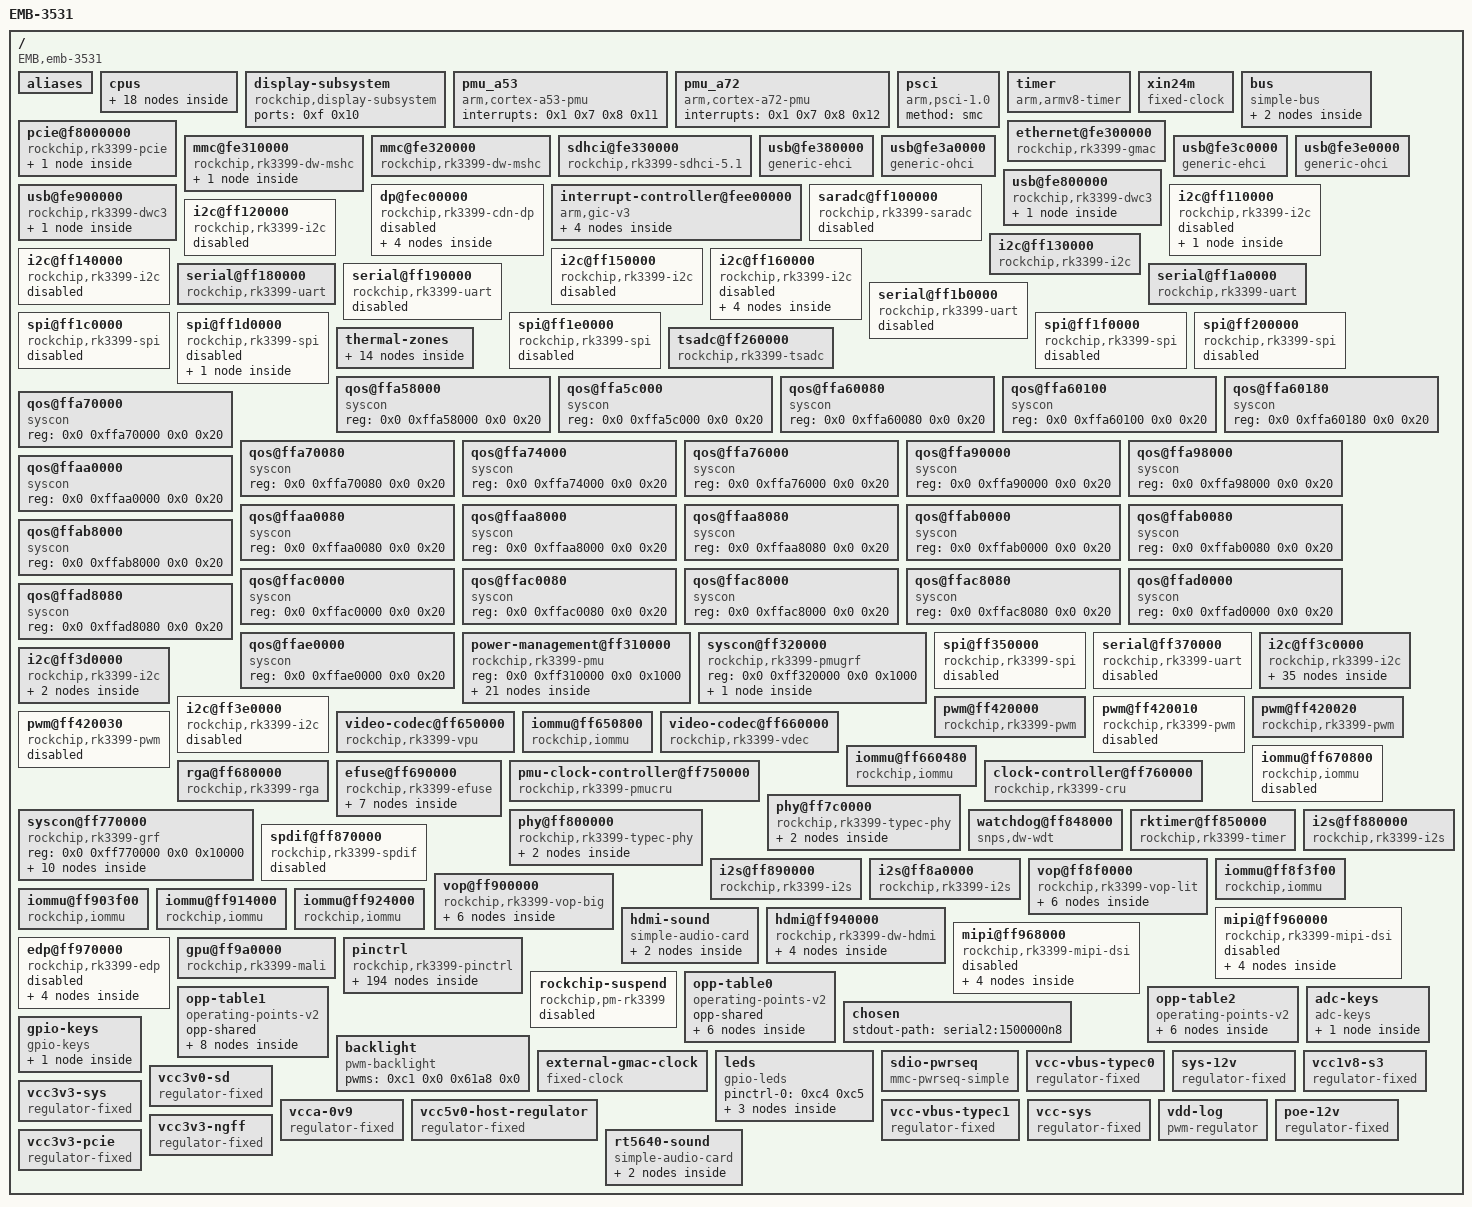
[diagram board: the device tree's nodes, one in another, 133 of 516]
/dts-v1/;

/ {
	compatible = "EMB,emb-3531", "rockchip,rk3399";
	interrupt-parent = <0x1>;
	#address-cells = <0x2>;
	#size-cells = <0x2>;
	model = "EMB-3531";

	aliases {
		ethernet0 = "/ethernet@fe300000";
		i2c0 = "/i2c@ff3c0000";
		i2c1 = "/i2c@ff110000";
		i2c2 = "/i2c@ff120000";
		i2c3 = "/i2c@ff130000";
		i2c4 = "/i2c@ff3d0000";
		i2c5 = "/i2c@ff140000";
		i2c6 = "/i2c@ff150000";
		i2c7 = "/i2c@ff160000";
		i2c8 = "/i2c@ff3e0000";
		mmc0 = "/mmc@fe310000";
		mmc1 = "/mmc@fe320000";
		mmc2 = "/sdhci@fe330000";
		serial0 = "/serial@ff180000";
		serial1 = "/serial@ff190000";
		serial2 = "/serial@ff1a0000";
		serial3 = "/serial@ff1b0000";
		serial4 = "/serial@ff370000";
	};

	cpus {
		#address-cells = <0x2>;
		#size-cells = <0x0>;

		cpu-map {

			cluster0 {

				core0 {
					cpu = <0x2>;
				};

				core1 {
					cpu = <0x3>;
				};

				core2 {
					cpu = <0x4>;
				};

				core3 {
					cpu = <0x5>;
				};
			};

			cluster1 {

				core0 {
					cpu = <0x6>;
				};

				core1 {
					cpu = <0x7>;
				};
			};
		};

		cpu@0 {
			device_type = "cpu";
			compatible = "arm,cortex-a53";
			reg = <0x0 0x0>;
			enable-method = "psci";
			capacity-dmips-mhz = <0x1e5>;
			clocks = <0x8 0x8>;
			#cooling-cells = <0x2>;
			dynamic-power-coefficient = <0x64>;
			cpu-idle-states = <0x9 0xa>;
			operating-points-v2 = <0xb>;
			cpu-supply = <0xc>;
			phandle = <0x2>;
		};

		cpu@1 {
			device_type = "cpu";
			compatible = "arm,cortex-a53";
			reg = <0x0 0x1>;
			enable-method = "psci";
			capacity-dmips-mhz = <0x1e5>;
			clocks = <0x8 0x8>;
			#cooling-cells = <0x2>;
			dynamic-power-coefficient = <0x64>;
			cpu-idle-states = <0x9 0xa>;
			operating-points-v2 = <0xb>;
			cpu-supply = <0xc>;
			phandle = <0x3>;
		};

		cpu@2 {
			device_type = "cpu";
			compatible = "arm,cortex-a53";
			reg = <0x0 0x2>;
			enable-method = "psci";
			capacity-dmips-mhz = <0x1e5>;
			clocks = <0x8 0x8>;
			#cooling-cells = <0x2>;
			dynamic-power-coefficient = <0x64>;
			cpu-idle-states = <0x9 0xa>;
			operating-points-v2 = <0xb>;
			cpu-supply = <0xc>;
			phandle = <0x4>;
		};

		cpu@3 {
			device_type = "cpu";
			compatible = "arm,cortex-a53";
			reg = <0x0 0x3>;
			enable-method = "psci";
			capacity-dmips-mhz = <0x1e5>;
			clocks = <0x8 0x8>;
			#cooling-cells = <0x2>;
			dynamic-power-coefficient = <0x64>;
			cpu-idle-states = <0x9 0xa>;
			operating-points-v2 = <0xb>;
			cpu-supply = <0xc>;
			phandle = <0x5>;
		};

		cpu@100 {
			device_type = "cpu";
			compatible = "arm,cortex-a72";
			reg = <0x0 0x100>;
			enable-method = "psci";
			capacity-dmips-mhz = <0x400>;
			clocks = <0x8 0x9>;
			#cooling-cells = <0x2>;
			dynamic-power-coefficient = <0x1b4>;
			cpu-idle-states = <0x9 0xa>;
			operating-points-v2 = <0xd>;
			cpu-supply = <0xe>;
			phandle = <0x6>;
		};

		cpu@101 {
			device_type = "cpu";
			compatible = "arm,cortex-a72";
			reg = <0x0 0x101>;
			enable-method = "psci";
			capacity-dmips-mhz = <0x400>;
			clocks = <0x8 0x9>;
			#cooling-cells = <0x2>;
			dynamic-power-coefficient = <0x1b4>;
			cpu-idle-states = <0x9 0xa>;
			operating-points-v2 = <0xd>;
			cpu-supply = <0xe>;
			phandle = <0x7>;
		};

		idle-states {
			entry-method = "psci";

			cpu-sleep {
				compatible = "arm,idle-state";
				local-timer-stop;
				arm,psci-suspend-param = <0x10000>;
				entry-latency-us = <0x78>;
				exit-latency-us = <0xfa>;
				min-residency-us = <0x384>;
				phandle = <0x9>;
			};

			cluster-sleep {
				compatible = "arm,idle-state";
				local-timer-stop;
				arm,psci-suspend-param = <0x1010000>;
				entry-latency-us = <0x190>;
				exit-latency-us = <0x1f4>;
				min-residency-us = <0x7d0>;
				phandle = <0xa>;
			};
		};
	};

	display-subsystem {
		compatible = "rockchip,display-subsystem";
		ports = <0xf 0x10>;
	};

	pmu_a53 {
		compatible = "arm,cortex-a53-pmu";
		interrupts = <0x1 0x7 0x8 0x11>;
	};

	pmu_a72 {
		compatible = "arm,cortex-a72-pmu";
		interrupts = <0x1 0x7 0x8 0x12>;
	};

	psci {
		compatible = "arm,psci-1.0";
		method = "smc";
	};

	timer {
		compatible = "arm,armv8-timer";
		interrupts = <0x1 0xd 0x8 0x0 0x1 0xe 0x8 0x0 0x1 0xb 0x8 0x0 0x1 0xa 0x8 0x0>;
		arm,no-tick-in-suspend;
	};

	xin24m {
		compatible = "fixed-clock";
		clock-frequency = <0x16e3600>;
		clock-output-names = "xin24m";
		#clock-cells = <0x0>;
		phandle = <0xd4>;
	};

	bus {
		compatible = "simple-bus";
		#address-cells = <0x2>;
		#size-cells = <0x2>;
		ranges;
		phandle = <0xd5>;

		dma-controller@ff6d0000 {
			compatible = "arm,pl330", "arm,primecell";
			reg = <0x0 0xff6d0000 0x0 0x4000>;
			interrupts = <0x0 0x5 0x4 0x0 0x0 0x6 0x4 0x0>;
			#dma-cells = <0x1>;
			arm,pl330-periph-burst;
			clocks = <0x8 0xd3>;
			clock-names = "apb_pclk";
			phandle = <0x62>;
		};

		dma-controller@ff6e0000 {
			compatible = "arm,pl330", "arm,primecell";
			reg = <0x0 0xff6e0000 0x0 0x4000>;
			interrupts = <0x0 0x7 0x4 0x0 0x0 0x8 0x4 0x0>;
			#dma-cells = <0x1>;
			arm,pl330-periph-burst;
			clocks = <0x8 0xd4>;
			clock-names = "apb_pclk";
			phandle = <0x51>;
		};
	};

	pcie@f8000000 {
		compatible = "rockchip,rk3399-pcie";
		reg = <0x0 0xf8000000 0x0 0x2000000 0x0 0xfd000000 0x0 0x1000000>;
		reg-names = "axi-base", "apb-base";
		device_type = "pci";
		#address-cells = <0x3>;
		#size-cells = <0x2>;
		#interrupt-cells = <0x1>;
		aspm-no-l0s;
		bus-range = <0x0 0x1f>;
		clocks = <0x8 0xc5 0x8 0xc4 0x8 0x147 0x8 0xa0>;
		clock-names = "aclk", "aclk-perf", "hclk", "pm";
		interrupts = <0x0 0x31 0x4 0x0 0x0 0x32 0x4 0x0 0x0 0x33 0x4 0x0>;
		interrupt-names = "sys", "legacy", "client";
		interrupt-map-mask = <0x0 0x0 0x0 0x7>;
		interrupt-map = <0x0 0x0 0x0 0x1 0x13 0x0 0x0 0x0 0x0 0x2 0x13 0x1 0x0 0x0 0x0 0x3 0x13 0x2 0x0 0x0 0x0 0x4 0x13 0x3>;
		max-link-speed = <0x2>;
		msi-map = <0x0 0x14 0x0 0x1000>;
		phys = <0x15 0x0 0x15 0x1 0x15 0x2 0x15 0x3>;
		phy-names = "pcie-phy-0", "pcie-phy-1", "pcie-phy-2", "pcie-phy-3";
		ranges = <0x83000000 0x0 0xfa000000 0x0 0xfa000000 0x0 0x1e00000 0x81000000 0x0 0xfbe00000 0x0 0xfbe00000 0x0 0x100000>;
		resets = <0x8 0x82 0x8 0x83 0x8 0x84 0x8 0x85 0x8 0x86 0x8 0x81 0x8 0x80>;
		reset-names = "core", "mgmt", "mgmt-sticky", "pipe", "pm", "pclk", "aclk";
		status = "okay";
		ep-gpios = <0x16 0x19 0x0>;
		num-lanes = <0x4>;
		pinctrl-names = "default";
		pinctrl-0 = <0x17>;
		vpcie3v3-supply = <0x18>;
		vpcie1v8-supply = <0x19>;
		vpcie0v9-supply = <0x1a>;
		phandle = <0xd6>;

		interrupt-controller {
			interrupt-controller;
			#address-cells = <0x0>;
			#interrupt-cells = <0x1>;
			phandle = <0x13>;
		};
	};

	ethernet@fe300000 {
		compatible = "rockchip,rk3399-gmac";
		reg = <0x0 0xfe300000 0x0 0x10000>;
		interrupts = <0x0 0xc 0x4 0x0>;
		interrupt-names = "macirq";
		clocks = <0x8 0x69 0x8 0x67 0x8 0x68 0x8 0x66 0x8 0x6a 0x8 0xd5 0x8 0x166>;
		clock-names = "stmmaceth", "mac_clk_rx", "mac_clk_tx", "clk_mac_ref", "clk_mac_refout", "aclk_mac", "pclk_mac";
		power-domains = <0x1b 0x16>;
		resets = <0x8 0x89>;
		reset-names = "stmmaceth";
		rockchip,grf = <0x1c>;
		snps,txpbl = <0x4>;
		status = "okay";
		assigned-clocks = <0x8 0xa6>;
		assigned-clock-parents = <0x1d>;
		clock_in_out = "input";
		phy-supply = <0x1e>;
		phy-mode = "rgmii";
		pinctrl-names = "default";
		pinctrl-0 = <0x1f>;
		snps,reset-gpio = <0x20 0xf 0x1>;
		snps,reset-active-low;
		snps,reset-delays-us = <0x0 0x2710 0xc350>;
		tx_delay = <0x28>;
		rx_delay = <0x11>;
		phandle = <0xd7>;
	};

	mmc@fe310000 {
		compatible = "rockchip,rk3399-dw-mshc", "rockchip,rk3288-dw-mshc";
		reg = <0x0 0xfe310000 0x0 0x4000>;
		interrupts = <0x0 0x40 0x4 0x0>;
		max-frequency = <0x8f0d180>;
		clocks = <0x8 0x1ee 0x8 0x4d 0x8 0x9c 0x8 0x9d>;
		clock-names = "biu", "ciu", "ciu-drive", "ciu-sample";
		fifo-depth = <0x100>;
		power-domains = <0x1b 0x1c>;
		resets = <0x8 0x79>;
		reset-names = "reset";
		status = "okay";
		bus-width = <0x4>;
		cap-sd-highspeed;
		cap-sdio-irq;
		keep-power-in-suspend;
		mmc-pwrseq = <0x21>;
		non-removable;
		pinctrl-names = "default";
		pinctrl-0 = <0x22 0x23 0x24>;
		sd-uhs-sdr104;
		vmmc-supply = "/i2c@ff3c0000/pmic@1b/regulators/LDO_REG4";
		vqmmc-supply = "/vcc1v8-s3";
		num-slots = <0x1>;
		phandle = <0xd8>;

		wifi@1 {
			compatible = "brcm,bcm4329-fmac";
			interrupt-parent = <0x25>;
			interrupts = <0x3 0x0>;
			interrupt-names = "host-wake";
			brcm,drive-strength = <0x5>;
			pinctrl-names = "default";
			pinctrl-0 = <0x26>;
			phandle = <0xd9>;
		};
	};

	mmc@fe320000 {
		compatible = "rockchip,rk3399-dw-mshc", "rockchip,rk3288-dw-mshc";
		reg = <0x0 0xfe320000 0x0 0x4000>;
		interrupts = <0x0 0x41 0x4 0x0>;
		max-frequency = <0x8f0d180>;
		assigned-clocks = <0x8 0x1cd>;
		assigned-clock-rates = <0xbebc200>;
		clocks = <0x8 0x1ce 0x8 0x4c 0x8 0x9a 0x8 0x9b>;
		clock-names = "biu", "ciu", "ciu-drive", "ciu-sample";
		fifo-depth = <0x100>;
		power-domains = <0x1b 0x1b>;
		resets = <0x8 0x7a>;
		reset-names = "reset";
		status = "okay";
		bus-width = <0x4>;
		cap-sd-highspeed;
		cd-gpios = <0x25 0x7 0x1>;
		disable-wp;
		pinctrl-names = "default";
		pinctrl-0 = <0x27 0x28 0x29>;
		sd-uhs-sdr104;
		vmmc-supply = <0x2a>;
		vqmmc-supply = <0x2b>;
		phandle = <0xda>;
	};

	sdhci@fe330000 {
		compatible = "rockchip,rk3399-sdhci-5.1", "arasan,sdhci-5.1";
		reg = <0x0 0xfe330000 0x0 0x10000>;
		interrupts = <0x0 0xb 0x4 0x0>;
		arasan,soc-ctl-syscon = <0x1c>;
		assigned-clocks = <0x8 0x4e>;
		assigned-clock-rates = <0xbebc200>;
		clocks = <0x8 0x4e 0x8 0xf0>;
		clock-names = "clk_xin", "clk_ahb";
		clock-output-names = "emmc_cardclock";
		#clock-cells = <0x0>;
		phys = <0x2c>;
		phy-names = "phy_arasan";
		power-domains = <0x1b 0x17>;
		disable-cqe-dcmd;
		status = "okay";
		bus-width = <0x8>;
		non-removable;
		phandle = <0x9b>;
	};

	usb@fe380000 {
		compatible = "generic-ehci";
		reg = <0x0 0xfe380000 0x0 0x20000>;
		interrupts = <0x0 0x1a 0x4 0x0>;
		clocks = <0x8 0x1c8 0x8 0x1c9 0x2d>;
		phys = <0x2e>;
		phy-names = "usb";
		status = "okay";
		phandle = <0xdb>;
	};

	usb@fe3a0000 {
		compatible = "generic-ohci";
		reg = <0x0 0xfe3a0000 0x0 0x20000>;
		interrupts = <0x0 0x1c 0x4 0x0>;
		clocks = <0x8 0x1c8 0x8 0x1c9 0x2d>;
		phys = <0x2e>;
		phy-names = "usb";
		status = "okay";
		phandle = <0xdc>;
	};

	usb@fe3c0000 {
		compatible = "generic-ehci";
		reg = <0x0 0xfe3c0000 0x0 0x20000>;
		interrupts = <0x0 0x1e 0x4 0x0>;
		clocks = <0x8 0x1ca 0x8 0x1cb 0x2f>;
		phys = <0x30>;
		phy-names = "usb";
		status = "okay";
		phandle = <0xdd>;
	};

	usb@fe3e0000 {
		compatible = "generic-ohci";
		reg = <0x0 0xfe3e0000 0x0 0x20000>;
		interrupts = <0x0 0x20 0x4 0x0>;
		clocks = <0x8 0x1ca 0x8 0x1cb 0x2f>;
		phys = <0x30>;
		phy-names = "usb";
		status = "okay";
		phandle = <0xde>;
	};

	usb@fe800000 {
		compatible = "rockchip,rk3399-dwc3";
		#address-cells = <0x2>;
		#size-cells = <0x2>;
		ranges;
		clocks = <0x8 0x81 0x8 0x83 0x8 0xf6 0x8 0xf8 0x8 0xf4 0x8 0xf9>;
		clock-names = "ref_clk", "suspend_clk", "bus_clk", "aclk_usb3_rksoc_axi_perf", "aclk_usb3", "grf_clk";
		resets = <0x8 0x125>;
		reset-names = "usb3-otg";
		status = "okay";
		phandle = <0xdf>;

		usb@fe800000 {
			compatible = "snps,dwc3";
			reg = <0x0 0xfe800000 0x0 0x100000>;
			interrupts = <0x0 0x69 0x4 0x0>;
			clocks = <0x8 0x81 0x8 0xf6 0x8 0x83>;
			clock-names = "ref", "bus_early", "suspend";
			dr_mode = "otg";
			phys = <0x31 0x32>;
			phy-names = "usb2-phy", "usb3-phy";
			phy_type = "utmi_wide";
			snps,dis_enblslpm_quirk;
			snps,dis-u2-freeclk-exists-quirk;
			snps,dis_u2_susphy_quirk;
			snps,dis-del-phy-power-chg-quirk;
			snps,dis-tx-ipgap-linecheck-quirk;
			snps,xhci-trb-ent-quirk;
			power-domains = <0x1b 0x18>;
			status = "okay";
			phandle = <0xe0>;
		};
	};

	usb@fe900000 {
		compatible = "rockchip,rk3399-dwc3";
		#address-cells = <0x2>;
		#size-cells = <0x2>;
		ranges;
		clocks = <0x8 0x82 0x8 0x84 0x8 0xf7 0x8 0xf8 0x8 0xf4 0x8 0xf9>;
		clock-names = "ref_clk", "suspend_clk", "bus_clk", "aclk_usb3_rksoc_axi_perf", "aclk_usb3", "grf_clk";
		resets = <0x8 0x126>;
		reset-names = "usb3-otg";
		status = "okay";
		phandle = <0xe1>;

		usb@fe900000 {
			compatible = "snps,dwc3";
			reg = <0x0 0xfe900000 0x0 0x100000>;
			interrupts = <0x0 0x6e 0x4 0x0>;
			clocks = <0x8 0x82 0x8 0xf7 0x8 0x84>;
			clock-names = "ref", "bus_early", "suspend";
			dr_mode = "host";
			phys = <0x33 0x34>;
			phy-names = "usb2-phy", "usb3-phy";
			phy_type = "utmi_wide";
			snps,dis_enblslpm_quirk;
			snps,dis-u2-freeclk-exists-quirk;
			snps,dis_u2_susphy_quirk;
			snps,dis-del-phy-power-chg-quirk;
			snps,dis-tx-ipgap-linecheck-quirk;
			snps,xhci-trb-ent-quirk;
			power-domains = <0x1b 0x18>;
			status = "okay";
			phandle = <0xe2>;
		};
	};

	dp@fec00000 {
		compatible = "rockchip,rk3399-cdn-dp";
		reg = <0x0 0xfec00000 0x0 0x100000>;
		interrupts = <0x0 0x9 0x4 0x0>;
		assigned-clocks = <0x8 0x72 0x8 0xa1>;
		assigned-clock-rates = <0x5f5e100 0xbebc200>;
		clocks = <0x8 0x72 0x8 0x175 0x8 0xa1 0x8 0x16f>;
		clock-names = "core-clk", "pclk", "spdif", "grf";
		phys = <0x35 0x36>;
		power-domains = <0x1b 0x15>;
		resets = <0x8 0x103 0x8 0x148 0x8 0x14a 0x8 0xfd>;
		reset-names = "spdif", "dptx", "apb", "core";
		rockchip,grf = <0x1c>;
		#sound-dai-cells = <0x1>;
		status = "disabled";
		phandle = <0xe3>;

		ports {

			port {
				#address-cells = <0x1>;
				#size-cells = <0x0>;
				phandle = <0xe4>;

				endpoint@0 {
					reg = <0x0>;
					remote-endpoint = <0x37>;
					phandle = <0xaa>;
				};

				endpoint@1 {
					reg = <0x1>;
					remote-endpoint = <0x38>;
					phandle = <0xa4>;
				};
			};
		};
	};

	interrupt-controller@fee00000 {
		compatible = "arm,gic-v3";
		#interrupt-cells = <0x4>;
		#address-cells = <0x2>;
		#size-cells = <0x2>;
		ranges;
		interrupt-controller;
		reg = <0x0 0xfee00000 0x0 0x10000 0x0 0xfef00000 0x0 0xc0000 0x0 0xfff00000 0x0 0x10000 0x0 0xfff10000 0x0 0x10000 0x0 0xfff20000 0x0 0x10000>;
		interrupts = <0x1 0x9 0x4 0x0>;
		phandle = <0x1>;

		interrupt-controller@fee20000 {
			compatible = "arm,gic-v3-its";
			msi-controller;
			#msi-cells = <0x1>;
			reg = <0x0 0xfee20000 0x0 0x20000>;
			phandle = <0x14>;
		};

		ppi-partitions {

			interrupt-partition-0 {
				affinity = <0x2 0x3 0x4 0x5>;
				phandle = <0x11>;
			};

			interrupt-partition-1 {
				affinity = <0x6 0x7>;
				phandle = <0x12>;
			};
		};
	};

	saradc@ff100000 {
		compatible = "rockchip,rk3399-saradc";
		reg = <0x0 0xff100000 0x0 0x100>;
		interrupts = <0x0 0x3e 0x4 0x0>;
		#io-channel-cells = <0x1>;
		clocks = <0x8 0x50 0x8 0x165>;
		clock-names = "saradc", "apb_pclk";
		resets = <0x8 0xd4>;
		reset-names = "saradc-apb";
		status = "disabled";
		vref-supply = <0x39>;
		phandle = <0xc2>;
	};

	i2c@ff110000 {
		compatible = "rockchip,rk3399-i2c";
		reg = <0x0 0xff110000 0x0 0x1000>;
		assigned-clocks = <0x8 0x41>;
		assigned-clock-rates = <0xbebc200>;
		clocks = <0x8 0x41 0x8 0x155>;
		clock-names = "i2c", "pclk";
		interrupts = <0x0 0x3b 0x4 0x0>;
		pinctrl-names = "default";
		pinctrl-0 = <0x3a>;
		#address-cells = <0x1>;
		#size-cells = <0x0>;
		status = "disabled";
		i2c-scl-rising-time-ns = <0x12c>;
		i2c-scl-falling-time-ns = <0xf>;
		phandle = <0xe5>;

		rt5640@1c {
			compatible = "realtek,rt5640";
			reg = <0x1c>;
			clocks = <0x8 0x59>;
			clock-names = "mclk";
			realtek,in1-differential;
			#sound-dai-cells = <0x0>;
			pinctrl-names = "default";
			pinctrl-0 = <0x3b>;
			phandle = <0xd3>;
		};
	};

	i2c@ff120000 {
		compatible = "rockchip,rk3399-i2c";
		reg = <0x0 0xff120000 0x0 0x1000>;
		assigned-clocks = <0x8 0x42>;
		assigned-clock-rates = <0xbebc200>;
		clocks = <0x8 0x42 0x8 0x156>;
		clock-names = "i2c", "pclk";
		interrupts = <0x0 0x23 0x4 0x0>;
		pinctrl-names = "default";
		pinctrl-0 = <0x3c>;
		#address-cells = <0x1>;
		#size-cells = <0x0>;
		status = "disabled";
		phandle = <0xe6>;
	};

	i2c@ff130000 {
		compatible = "rockchip,rk3399-i2c";
		reg = <0x0 0xff130000 0x0 0x1000>;
		assigned-clocks = <0x8 0x43>;
		assigned-clock-rates = <0xbebc200>;
		clocks = <0x8 0x43 0x8 0x157>;
		clock-names = "i2c", "pclk";
		interrupts = <0x0 0x22 0x4 0x0>;
		pinctrl-names = "default";
		pinctrl-0 = <0x3d>;
		#address-cells = <0x1>;
		#size-cells = <0x0>;
		status = "okay";
		i2c-scl-rising-time-ns = <0x1c2>;
		i2c-scl-falling-time-ns = <0xf>;
		phandle = <0xad>;
	};

	i2c@ff140000 {
		compatible = "rockchip,rk3399-i2c";
		reg = <0x0 0xff140000 0x0 0x1000>;
		assigned-clocks = <0x8 0x44>;
		assigned-clock-rates = <0xbebc200>;
		clocks = <0x8 0x44 0x8 0x158>;
		clock-names = "i2c", "pclk";
		interrupts = <0x0 0x26 0x4 0x0>;
		pinctrl-names = "default";
		pinctrl-0 = <0x3e>;
		#address-cells = <0x1>;
		#size-cells = <0x0>;
		status = "disabled";
		phandle = <0xe7>;
	};

	i2c@ff150000 {
		compatible = "rockchip,rk3399-i2c";
		reg = <0x0 0xff150000 0x0 0x1000>;
		assigned-clocks = <0x8 0x45>;
		assigned-clock-rates = <0xbebc200>;
		clocks = <0x8 0x45 0x8 0x159>;
		clock-names = "i2c", "pclk";
		interrupts = <0x0 0x25 0x4 0x0>;
		pinctrl-names = "default";
		pinctrl-0 = <0x3f>;
		#address-cells = <0x1>;
		#size-cells = <0x0>;
		status = "disabled";
		phandle = <0xe8>;
	};

	i2c@ff160000 {
		compatible = "rockchip,rk3399-i2c";
		reg = <0x0 0xff160000 0x0 0x1000>;
		assigned-clocks = <0x8 0x46>;
		assigned-clock-rates = <0xbebc200>;
		clocks = <0x8 0x46 0x8 0x15a>;
		clock-names = "i2c", "pclk";
		interrupts = <0x0 0x24 0x4 0x0>;
		pinctrl-names = "default";
		pinctrl-0 = <0x40>;
		#address-cells = <0x1>;
		#size-cells = <0x0>;
		status = "disabled";
		i2c-scl-rising-time-ns = <0x258>;
		i2c-scl-falling-time-ns = <0x14>;
		phandle = <0xe9>;

		usb-typec@22 {
			compatible = "fairchild,fusb302";
			reg = <0x22>;
			interrupt-parent = <0x41>;
			interrupts = <0x2 0x8>;
			pinctrl-names = "default";
			pinctrl-0 = <0x42>;
			vbus-supply = <0x43>;
			status = "okay";
			phandle = <0xea>;
		};

		regulator@66 {
			compatible = "mps,mp8859";
			reg = <0x66>;
			phandle = <0xeb>;

			mp8859_dcdc {
				regulator-name = "dc_12v";
				regulator-min-microvolt = <0xb71b00>;
				regulator-max-microvolt = <0xb71b00>;
				regulator-always-on;
				regulator-boot-on;
				vin-supply = <0x43>;
				phandle = <0xec>;

				regulator-state-mem {
					regulator-on-in-suspend;
					regulator-suspend-microvolt = <0xb71b00>;
				};
			};
		};
	};

	serial@ff180000 {
		compatible = "rockchip,rk3399-uart", "snps,dw-apb-uart";
		reg = <0x0 0xff180000 0x0 0x100>;
		clocks = <0x8 0x51 0x8 0x160>;
		clock-names = "baudclk", "apb_pclk";
		interrupts = <0x0 0x63 0x4 0x0>;
		reg-shift = <0x2>;
		reg-io-width = <0x4>;
		pinctrl-names = "default";
		pinctrl-0 = <0x44 0x45 0x46>;
		status = "okay";
		phandle = <0xed>;
	};

	serial@ff190000 {
		compatible = "rockchip,rk3399-uart", "snps,dw-apb-uart";
		reg = <0x0 0xff190000 0x0 0x100>;
		clocks = <0x8 0x52 0x8 0x161>;
		clock-names = "baudclk", "apb_pclk";
		interrupts = <0x0 0x62 0x4 0x0>;
		reg-shift = <0x2>;
		reg-io-width = <0x4>;
		pinctrl-names = "default";
		pinctrl-0 = <0x4e>;
		status = "disabled";
		phandle = <0xee>;
	};

	serial@ff1a0000 {
		compatible = "rockchip,rk3399-uart", "snps,dw-apb-uart";
		reg = <0x0 0xff1a0000 0x0 0x100>;
		clocks = <0x8 0x53 0x8 0x162>;
		clock-names = "baudclk", "apb_pclk";
		interrupts = <0x0 0x64 0x4 0x0>;
		reg-shift = <0x2>;
		reg-io-width = <0x4>;
		pinctrl-names = "default";
		pinctrl-0 = <0x4f>;
		status = "okay";
		phandle = <0xef>;
	};

	serial@ff1b0000 {
		compatible = "rockchip,rk3399-uart", "snps,dw-apb-uart";
		reg = <0x0 0xff1b0000 0x0 0x100>;
		clocks = <0x8 0x54 0x8 0x163>;
		clock-names = "baudclk", "apb_pclk";
		interrupts = <0x0 0x65 0x4 0x0>;
		reg-shift = <0x2>;
		reg-io-width = <0x4>;
		pinctrl-names = "default";
		pinctrl-0 = <0x50>;
		status = "disabled";
		phandle = <0xf0>;
	};

	spi@ff1c0000 {
		compatible = "rockchip,rk3399-spi", "rockchip,rk3066-spi";
		reg = <0x0 0xff1c0000 0x0 0x1000>;
		clocks = <0x8 0x47 0x8 0x15b>;
		clock-names = "spiclk", "apb_pclk";
		interrupts = <0x0 0x44 0x4 0x0>;
		dmas = <0x51 0xa 0x51 0xb>;
		dma-names = "tx", "rx";
		pinctrl-names = "default";
		pinctrl-0 = <0x52 0x53 0x54 0x55>;
		#address-cells = <0x1>;
		#size-cells = <0x0>;
		status = "disabled";
		phandle = <0xf1>;
	};

	spi@ff1d0000 {
		compatible = "rockchip,rk3399-spi", "rockchip,rk3066-spi";
		reg = <0x0 0xff1d0000 0x0 0x1000>;
		clocks = <0x8 0x48 0x8 0x15c>;
		clock-names = "spiclk", "apb_pclk";
		interrupts = <0x0 0x35 0x4 0x0>;
		dmas = <0x51 0xc 0x51 0xd>;
		dma-names = "tx", "rx";
		pinctrl-names = "default";
		pinctrl-0 = <0x56 0x57 0x58 0x59>;
		#address-cells = <0x1>;
		#size-cells = <0x0>;
		status = "disabled";
		phandle = <0xf2>;

		flash@0 {
			compatible = "jedec,spi-nor";
			reg = <0x0>;
			spi-max-frequency = <0x989680>;
		};
	};

	spi@ff1e0000 {
		compatible = "rockchip,rk3399-spi", "rockchip,rk3066-spi";
		reg = <0x0 0xff1e0000 0x0 0x1000>;
		clocks = <0x8 0x49 0x8 0x15d>;
		clock-names = "spiclk", "apb_pclk";
		interrupts = <0x0 0x34 0x4 0x0>;
		dmas = <0x51 0xe 0x51 0xf>;
		dma-names = "tx", "rx";
		pinctrl-names = "default";
		pinctrl-0 = <0x5a 0x5b 0x5c 0x5d>;
		#address-cells = <0x1>;
		#size-cells = <0x0>;
		status = "disabled";
		phandle = <0xf3>;
	};

	spi@ff1f0000 {
		compatible = "rockchip,rk3399-spi", "rockchip,rk3066-spi";
		reg = <0x0 0xff1f0000 0x0 0x1000>;
		clocks = <0x8 0x4a 0x8 0x15e>;
		clock-names = "spiclk", "apb_pclk";
		interrupts = <0x0 0x43 0x4 0x0>;
		dmas = <0x51 0x12 0x51 0x13>;
		dma-names = "tx", "rx";
		pinctrl-names = "default";
		pinctrl-0 = <0x5e 0x5f 0x60 0x61>;
		#address-cells = <0x1>;
		#size-cells = <0x0>;
		status = "disabled";
		phandle = <0xf4>;
	};

	spi@ff200000 {
		compatible = "rockchip,rk3399-spi", "rockchip,rk3066-spi";
		reg = <0x0 0xff200000 0x0 0x1000>;
		clocks = <0x8 0x4b 0x8 0x15f>;
		clock-names = "spiclk", "apb_pclk";
		interrupts = <0x0 0x84 0x4 0x0>;
		dmas = <0x62 0x8 0x62 0x9>;
		dma-names = "tx", "rx";
		pinctrl-names = "default";
		pinctrl-0 = <0x63 0x64 0x65 0x66>;
		power-domains = <0x1b 0x1c>;
		#address-cells = <0x1>;
		#size-cells = <0x0>;
		status = "disabled";
		phandle = <0xf5>;
	};

	thermal-zones {
		phandle = <0xf6>;

		cpu {
			polling-delay-passive = <0x64>;
			polling-delay = <0x3e8>;
			thermal-sensors = <0x67 0x0>;
			phandle = <0xf7>;

			trips {

				cpu_alert0 {
					temperature = <0x14c08>;
					hysteresis = <0x7d0>;
					type = "passive";
					phandle = <0x68>;
				};

				cpu_alert1 {
					temperature = <0x17318>;
					hysteresis = <0x7d0>;
					type = "passive";
					phandle = <0x69>;
				};

				cpu_crit {
					temperature = <0x186a0>;
					hysteresis = <0x7d0>;
					type = "critical";
					phandle = <0xf8>;
				};
			};

			cooling-maps {

				map0 {
					trip = <0x68>;
					cooling-device = <0x6 0xffffffff 0xffffffff 0x7 0xffffffff 0xffffffff>;
				};

				map1 {
					trip = <0x69>;
					cooling-device = <0x2 0xffffffff 0xffffffff 0x3 0xffffffff 0xffffffff 0x4 0xffffffff 0xffffffff 0x5 0xffffffff 0xffffffff 0x6 0xffffffff 0xffffffff 0x7 0xffffffff 0xffffffff>;
				};
			};
		};

		gpu {
			polling-delay-passive = <0x64>;
			polling-delay = <0x3e8>;
			thermal-sensors = <0x67 0x1>;
			phandle = <0xf9>;

			trips {

				gpu_alert0 {
					temperature = <0x124f8>;
					hysteresis = <0x7d0>;
					type = "passive";
					phandle = <0x6a>;
				};

				gpu_crit {
					temperature = <0x17318>;
					hysteresis = <0x7d0>;
					type = "critical";
					phandle = <0xfa>;
				};
			};

			cooling-maps {

				map0 {
					trip = <0x6a>;
					cooling-device = <0x6b 0xffffffff 0xffffffff>;
				};
			};
		};
	};

	tsadc@ff260000 {
		compatible = "rockchip,rk3399-tsadc";
		reg = <0x0 0xff260000 0x0 0x100>;
		interrupts = <0x0 0x61 0x4 0x0>;
		assigned-clocks = <0x8 0x4f>;
		assigned-clock-rates = <0xb71b0>;
		clocks = <0x8 0x4f 0x8 0x164>;
		clock-names = "tsadc", "apb_pclk";
		resets = <0x8 0xe8>;
		reset-names = "tsadc-apb";
		rockchip,grf = <0x1c>;
		rockchip,hw-tshut-temp = <0x17318>;
		pinctrl-names = "init", "default", "sleep";
		pinctrl-0 = <0x6c>;
		pinctrl-1 = <0x6d>;
		pinctrl-2 = <0x6c>;
		#thermal-sensor-cells = <0x1>;
		status = "okay";
		rockchip,hw-tshut-mode = <0x1>;
		rockchip,hw-tshut-polarity = <0x1>;
		phandle = <0x67>;
	};

	qos@ffa58000 {
		compatible = "syscon";
		reg = <0x0 0xffa58000 0x0 0x20>;
		phandle = <0x75>;
	};

	qos@ffa5c000 {
		compatible = "syscon";
		reg = <0x0 0xffa5c000 0x0 0x20>;
		phandle = <0x76>;
	};

	qos@ffa60080 {
		compatible = "syscon";
		reg = <0x0 0xffa60080 0x0 0x20>;
		phandle = <0xfb>;
	};

	qos@ffa60100 {
		compatible = "syscon";
		reg = <0x0 0xffa60100 0x0 0x20>;
		phandle = <0xfc>;
	};

	qos@ffa60180 {
		compatible = "syscon";
		reg = <0x0 0xffa60180 0x0 0x20>;
		phandle = <0xfd>;
	};

	qos@ffa70000 {
		compatible = "syscon";
		reg = <0x0 0xffa70000 0x0 0x20>;
		phandle = <0x79>;
	};

	qos@ffa70080 {
		compatible = "syscon";
		reg = <0x0 0xffa70080 0x0 0x20>;
		phandle = <0x7a>;
	};

	qos@ffa74000 {
		compatible = "syscon";
		reg = <0x0 0xffa74000 0x0 0x20>;
		phandle = <0x77>;
	};

	qos@ffa76000 {
		compatible = "syscon";
		reg = <0x0 0xffa76000 0x0 0x20>;
		phandle = <0x78>;
	};

	qos@ffa90000 {
		compatible = "syscon";
		reg = <0x0 0xffa90000 0x0 0x20>;
		phandle = <0x7b>;
	};

	qos@ffa98000 {
		compatible = "syscon";
		reg = <0x0 0xffa98000 0x0 0x20>;
		phandle = <0x6e>;
	};

	qos@ffaa0000 {
		compatible = "syscon";
		reg = <0x0 0xffaa0000 0x0 0x20>;
		phandle = <0x7c>;
	};

	qos@ffaa0080 {
		compatible = "syscon";
		reg = <0x0 0xffaa0080 0x0 0x20>;
		phandle = <0x7d>;
	};

	qos@ffaa8000 {
		compatible = "syscon";
		reg = <0x0 0xffaa8000 0x0 0x20>;
		phandle = <0x7e>;
	};

	qos@ffaa8080 {
		compatible = "syscon";
		reg = <0x0 0xffaa8080 0x0 0x20>;
		phandle = <0x7f>;
	};

	qos@ffab0000 {
		compatible = "syscon";
		reg = <0x0 0xffab0000 0x0 0x20>;
		phandle = <0x6f>;
	};

	qos@ffab0080 {
		compatible = "syscon";
		reg = <0x0 0xffab0080 0x0 0x20>;
		phandle = <0x70>;
	};

	qos@ffab8000 {
		compatible = "syscon";
		reg = <0x0 0xffab8000 0x0 0x20>;
		phandle = <0x71>;
	};

	qos@ffac0000 {
		compatible = "syscon";
		reg = <0x0 0xffac0000 0x0 0x20>;
		phandle = <0x72>;
	};

	qos@ffac0080 {
		compatible = "syscon";
		reg = <0x0 0xffac0080 0x0 0x20>;
		phandle = <0x73>;
	};

	qos@ffac8000 {
		compatible = "syscon";
		reg = <0x0 0xffac8000 0x0 0x20>;
		phandle = <0x80>;
	};

	qos@ffac8080 {
		compatible = "syscon";
		reg = <0x0 0xffac8080 0x0 0x20>;
		phandle = <0x81>;
	};

	qos@ffad0000 {
		compatible = "syscon";
		reg = <0x0 0xffad0000 0x0 0x20>;
		phandle = <0x82>;
	};

	qos@ffad8080 {
		compatible = "syscon";
		reg = <0x0 0xffad8080 0x0 0x20>;
		phandle = <0xfe>;
	};

	qos@ffae0000 {
		compatible = "syscon";
		reg = <0x0 0xffae0000 0x0 0x20>;
		phandle = <0x74>;
	};

	power-management@ff310000 {
		compatible = "rockchip,rk3399-pmu", "syscon", "simple-mfd";
		reg = <0x0 0xff310000 0x0 0x1000>;
		phandle = <0xff>;

		power-controller {
			compatible = "rockchip,rk3399-power-controller";
			#power-domain-cells = <0x1>;
			#address-cells = <0x1>;
			#size-cells = <0x0>;
			phandle = <0x1b>;

			power-domain@34 {
				reg = <0x22>;
				clocks = <0x8 0xe1 0x8 0x1dd>;
				pm_qos = <0x6e>;
			};

			power-domain@33 {
				reg = <0x21>;
				clocks = <0x8 0xdc 0x8 0x1e5>;
				pm_qos = <0x6f 0x70>;
			};

			power-domain@31 {
				reg = <0x1f>;
				clocks = <0x8 0xeb 0x8 0x1ea>;
				pm_qos = <0x71>;
			};

			power-domain@32 {
				reg = <0x20>;
				clocks = <0x8 0xed 0x8 0x1ec>;
				pm_qos = <0x72 0x73>;
			};

			power-domain@35 {
				reg = <0x23>;
				clocks = <0x8 0xd0>;
				pm_qos = <0x74>;
			};

			power-domain@25 {
				reg = <0x19>;
				clocks = <0x8 0x16c>;
			};

			power-domain@23 {
				reg = <0x17>;
				clocks = <0x8 0xf0>;
				pm_qos = <0x75>;
			};

			power-domain@22 {
				reg = <0x16>;
				clocks = <0x8 0xd5 0x8 0x166>;
				pm_qos = <0x76>;
			};

			power-domain@27 {
				reg = <0x1b>;
				clocks = <0x8 0x1ce 0x8 0x4c>;
				pm_qos = <0x77>;
			};

			power-domain@28 {
				reg = <0x1c>;
				clocks = <0x8 0x1ee>;
				pm_qos = <0x78>;
			};

			power-domain@8 {
				reg = <0x8>;
				clocks = <0x8 0x7e 0x8 0x7d>;
			};

			power-domain@9 {
				reg = <0x9>;
				clocks = <0x8 0x80 0x8 0x7f>;
			};

			power-domain@24 {
				reg = <0x18>;
				clocks = <0x8 0xf4>;
				pm_qos = <0x79 0x7a>;
			};

			power-domain@15 {
				reg = <0xf>;
				#address-cells = <0x1>;
				#size-cells = <0x0>;

				power-domain@21 {
					reg = <0x15>;
					clocks = <0x8 0xde 0x8 0x1e7 0x8 0x172>;
					pm_qos = <0x7b>;
				};

				power-domain@19 {
					reg = <0x13>;
					clocks = <0x8 0xe5 0x8 0x1df>;
					pm_qos = <0x7c 0x7d>;
				};

				power-domain@20 {
					reg = <0x14>;
					clocks = <0x8 0xe6 0x8 0x1e0>;
					pm_qos = <0x7e 0x7f>;
				};

				power-domain@16 {
					reg = <0x10>;
					#address-cells = <0x1>;
					#size-cells = <0x0>;

					power-domain@17 {
						reg = <0x11>;
						clocks = <0x8 0xd9 0x8 0x1d9>;
						pm_qos = <0x80 0x81>;
					};

					power-domain@18 {
						reg = <0x12>;
						clocks = <0x8 0xdb 0x8 0x1db>;
						pm_qos = <0x82>;
					};
				};
			};
		};
	};

	syscon@ff320000 {
		compatible = "rockchip,rk3399-pmugrf", "syscon", "simple-mfd";
		reg = <0x0 0xff320000 0x0 0x1000>;
		phandle = <0x98>;

		io-domains {
			compatible = "rockchip,rk3399-pmu-io-voltage-domain";
			status = "okay";
			pmu1830-supply = <0x83>;
			phandle = <0x100>;
		};
	};

	spi@ff350000 {
		compatible = "rockchip,rk3399-spi", "rockchip,rk3066-spi";
		reg = <0x0 0xff350000 0x0 0x1000>;
		clocks = <0x84 0x3 0x84 0x1f>;
		clock-names = "spiclk", "apb_pclk";
		interrupts = <0x0 0x3c 0x4 0x0>;
		pinctrl-names = "default";
		pinctrl-0 = <0x85 0x86 0x87 0x88>;
		#address-cells = <0x1>;
		#size-cells = <0x0>;
		status = "disabled";
		phandle = <0x101>;
	};

	serial@ff370000 {
		compatible = "rockchip,rk3399-uart", "snps,dw-apb-uart";
		reg = <0x0 0xff370000 0x0 0x100>;
		clocks = <0x84 0x6 0x84 0x22>;
		clock-names = "baudclk", "apb_pclk";
		interrupts = <0x0 0x66 0x4 0x0>;
		reg-shift = <0x2>;
		reg-io-width = <0x4>;
		pinctrl-names = "default";
		pinctrl-0 = <0x89>;
		status = "disabled";
		phandle = <0x102>;
	};

	i2c@ff3c0000 {
		compatible = "rockchip,rk3399-i2c";
		reg = <0x0 0xff3c0000 0x0 0x1000>;
		assigned-clocks = <0x84 0x9>;
		assigned-clock-rates = <0xbebc200>;
		clocks = <0x84 0x9 0x84 0x1b>;
		clock-names = "i2c", "pclk";
		interrupts = <0x0 0x39 0x4 0x0>;
		pinctrl-names = "default";
		pinctrl-0 = <0x8a>;
		#address-cells = <0x1>;
		#size-cells = <0x0>;
		status = "okay";
		clock-frequency = <0x61a80>;
		i2c-scl-rising-time-ns = <0xa8>;
		i2c-scl-falling-time-ns = <0x4>;
		phandle = <0x103>;

		pmic@1b {
			compatible = "rockchip,rk808";
			reg = <0x1b>;
			interrupt-parent = <0x41>;
			interrupts = <0x15 0x8>;
			#clock-cells = <0x1>;
			clock-output-names = "xin32k", "rk808-clkout2";
			pinctrl-names = "default";
			pinctrl-0 = <0x8b>;
			rockchip,system-power-controller;
			wakeup-source;
			vcc1-supply = <0x4c>;
			vcc2-supply = <0x4c>;
			vcc3-supply = <0x4c>;
			vcc4-supply = <0x4c>;
			vcc6-supply = <0x4c>;
			vcc7-supply = <0x4c>;
			vcc8-supply = <0x4c>;
			vcc9-supply = <0x4c>;
			vcc10-supply = <0x4c>;
			vcc11-supply = <0x4c>;
			vcc12-supply = <0x4c>;
			vcc13-supply = <0x4c>;
			vcc14-supply = <0x4c>;
			vddio-supply = <0x83>;
			phandle = <0x47>;

			regulators {

				DCDC_REG1 {
					regulator-name = "vdd_center";
					regulator-always-on;
					regulator-boot-on;
					regulator-min-microvolt = <0xb71b0>;
					regulator-max-microvolt = <0x149970>;
					regulator-ramp-delay = <0x1771>;
					phandle = <0x104>;

					regulator-state-mem {
						regulator-off-in-suspend;
					};
				};

				DCDC_REG2 {
					regulator-name = "vdd_cpu_l";
					regulator-always-on;
					regulator-boot-on;
					regulator-min-microvolt = <0xb71b0>;
					regulator-max-microvolt = <0x149970>;
					regulator-ramp-delay = <0x1771>;
					phandle = <0xc>;

					regulator-state-mem {
						regulator-off-in-suspend;
					};
				};

				DCDC_REG3 {
					regulator-name = "vcc_ddr";
					regulator-always-on;
					regulator-boot-on;
					phandle = <0x105>;

					regulator-state-mem {
						regulator-on-in-suspend;
					};
				};

				DCDC_REG4 {
					regulator-name = "vcc_1v8";
					regulator-always-on;
					regulator-boot-on;
					regulator-min-microvolt = <0x1b7740>;
					regulator-max-microvolt = <0x1b7740>;
					phandle = <0x4d>;

					regulator-state-mem {
						regulator-on-in-suspend;
						regulator-suspend-microvolt = <0x1b7740>;
					};
				};

				LDO_REG1 {
					regulator-name = "vcca1v8_codec";
					regulator-always-on;
					regulator-boot-on;
					regulator-min-microvolt = <0x1b7740>;
					regulator-max-microvolt = <0x1b7740>;
					phandle = <0x99>;

					regulator-state-mem {
						regulator-off-in-suspend;
					};
				};

				LDO_REG2 {
					regulator-name = "vcc1v8_hdmi";
					regulator-always-on;
					regulator-boot-on;
					regulator-min-microvolt = <0x1b7740>;
					regulator-max-microvolt = <0x1b7740>;
					phandle = <0x106>;

					regulator-state-mem {
						regulator-off-in-suspend;
					};
				};

				LDO_REG3 {
					regulator-name = "vcc1v8_pmu";
					regulator-always-on;
					regulator-boot-on;
					regulator-min-microvolt = <0x1b7740>;
					regulator-max-microvolt = <0x1b7740>;
					phandle = <0x19>;

					regulator-state-mem {
						regulator-on-in-suspend;
						regulator-suspend-microvolt = <0x1b7740>;
					};
				};

				LDO_REG4 {
					regulator-name = "vcc_sdio";
					regulator-always-on;
					regulator-boot-on;
					regulator-min-microvolt = <0x1b7740>;
					regulator-max-microvolt = <0x2dc6c0>;
					phandle = <0x2b>;

					regulator-state-mem {
						regulator-on-in-suspend;
						regulator-suspend-microvolt = <0x2dc6c0>;
					};
				};

				LDO_REG5 {
					regulator-name = "vcca3v0_codec";
					regulator-always-on;
					regulator-boot-on;
					regulator-min-microvolt = <0x2dc6c0>;
					regulator-max-microvolt = <0x2dc6c0>;
					phandle = <0x107>;

					regulator-state-mem {
						regulator-off-in-suspend;
					};
				};

				LDO_REG6 {
					regulator-name = "vcc_1v5";
					regulator-always-on;
					regulator-boot-on;
					regulator-min-microvolt = <0x16e360>;
					regulator-max-microvolt = <0x16e360>;
					phandle = <0x108>;

					regulator-state-mem {
						regulator-on-in-suspend;
						regulator-suspend-microvolt = <0x16e360>;
					};
				};

				LDO_REG7 {
					regulator-name = "vcca0v9_hdmi";
					regulator-always-on;
					regulator-boot-on;
					regulator-min-microvolt = <0xdbba0>;
					regulator-max-microvolt = <0xdbba0>;
					phandle = <0x109>;

					regulator-state-mem {
						regulator-off-in-suspend;
					};
				};

				LDO_REG8 {
					regulator-name = "vcc_3v0";
					regulator-always-on;
					regulator-boot-on;
					regulator-min-microvolt = <0x2dc6c0>;
					regulator-max-microvolt = <0x2dc6c0>;
					phandle = <0x83>;

					regulator-state-mem {
						regulator-on-in-suspend;
						regulator-suspend-microvolt = <0x2dc6c0>;
					};
				};

				SWITCH_REG1 {
					regulator-name = "vcc3v3_s3";
					regulator-always-on;
					regulator-boot-on;
					phandle = <0x1e>;

					regulator-state-mem {
						regulator-off-in-suspend;
					};
				};

				SWITCH_REG2 {
					regulator-name = "vcc3v3_s0";
					regulator-always-on;
					regulator-boot-on;
					phandle = <0x10a>;

					regulator-state-mem {
						regulator-off-in-suspend;
					};
				};
			};

			rtc {
				compatible = "rk808-rtc";
				status = "disabled";
			};
		};

		regulator@40 {
			compatible = "silergy,syr827";
			reg = <0x40>;
			fcs,suspend-voltage-selector = <0x1>;
			pinctrl-names = "default";
			pinctrl-0 = <0x8c>;
			regulator-name = "vdd_cpu_b";
			regulator-min-microvolt = <0xadf34>;
			regulator-max-microvolt = <0x16e360>;
			regulator-ramp-delay = <0x3e8>;
			regulator-always-on;
			regulator-boot-on;
			vin-supply = <0x4c>;
			phandle = <0xe>;

			regulator-state-mem {
				regulator-off-in-suspend;
			};
		};

		regulator@41 {
			compatible = "silergy,syr828";
			reg = <0x41>;
			fcs,suspend-voltage-selector = <0x1>;
			pinctrl-names = "default";
			pinctrl-0 = <0x8d>;
			regulator-name = "vdd_gpu";
			regulator-min-microvolt = <0xadf34>;
			regulator-max-microvolt = <0x16e360>;
			regulator-ramp-delay = <0x3e8>;
			regulator-always-on;
			regulator-boot-on;
			vin-supply = <0x4c>;
			phandle = <0xb9>;

			regulator-state-mem {
				regulator-off-in-suspend;
			};
		};
	};

	i2c@ff3d0000 {
		compatible = "rockchip,rk3399-i2c";
		reg = <0x0 0xff3d0000 0x0 0x1000>;
		assigned-clocks = <0x84 0xa>;
		assigned-clock-rates = <0xbebc200>;
		clocks = <0x84 0xa 0x84 0x1c>;
		clock-names = "i2c", "pclk";
		interrupts = <0x0 0x38 0x4 0x0>;
		pinctrl-names = "default";
		pinctrl-0 = <0x8e>;
		#address-cells = <0x1>;
		#size-cells = <0x0>;
		status = "okay";
		i2c-scl-rising-time-ns = <0x258>;
		i2c-scl-falling-time-ns = <0x14>;
		phandle = <0x10c>;

		usb-typec@22 {
			compatible = "fairchild,fusb302";
			reg = <0x22>;
			interrupt-parent = <0x41>;
			interrupts = <0x1 0x8>;
			pinctrl-names = "default";
			pinctrl-0 = <0x8f>;
			vbus-supply = <0x90>;
			status = "okay";
			phandle = <0x10d>;
		};

		accelerometer@68 {
			compatible = "invensense,mpu6500";
			reg = <0x68>;
			interrupt-parent = <0x41>;
			interrupts = <0x16 0x1>;
		};
	};

	i2c@ff3e0000 {
		compatible = "rockchip,rk3399-i2c";
		reg = <0x0 0xff3e0000 0x0 0x1000>;
		assigned-clocks = <0x84 0xb>;
		assigned-clock-rates = <0xbebc200>;
		clocks = <0x84 0xb 0x84 0x1d>;
		clock-names = "i2c", "pclk";
		interrupts = <0x0 0x3a 0x4 0x0>;
		pinctrl-names = "default";
		pinctrl-0 = <0x91>;
		#address-cells = <0x1>;
		#size-cells = <0x0>;
		status = "disabled";
		phandle = <0x10e>;
	};

	pwm@ff420000 {
		compatible = "rockchip,rk3399-pwm", "rockchip,rk3288-pwm";
		reg = <0x0 0xff420000 0x0 0x10>;
		#pwm-cells = <0x3>;
		pinctrl-names = "default";
		pinctrl-0 = <0x92>;
		clocks = <0x84 0x1e>;
		clock-names = "pwm";
		status = "okay";
		phandle = <0xc1>;
	};

	pwm@ff420010 {
		compatible = "rockchip,rk3399-pwm", "rockchip,rk3288-pwm";
		reg = <0x0 0xff420010 0x0 0x10>;
		#pwm-cells = <0x3>;
		pinctrl-names = "default";
		pinctrl-0 = <0x93>;
		clocks = <0x84 0x1e>;
		clock-names = "pwm";
		status = "disabled";
		phandle = <0x10f>;
	};

	pwm@ff420020 {
		compatible = "rockchip,rk3399-pwm", "rockchip,rk3288-pwm";
		reg = <0x0 0xff420020 0x0 0x10>;
		#pwm-cells = <0x3>;
		pinctrl-names = "default";
		pinctrl-0 = <0x94>;
		clocks = <0x84 0x1e>;
		clock-names = "pwm";
		status = "okay";
		phandle = <0xcf>;
	};

	pwm@ff420030 {
		compatible = "rockchip,rk3399-pwm", "rockchip,rk3288-pwm";
		reg = <0x0 0xff420030 0x0 0x10>;
		#pwm-cells = <0x3>;
		pinctrl-names = "default";
		pinctrl-0 = <0x95>;
		clocks = <0x84 0x1e>;
		clock-names = "pwm";
		status = "disabled";
		phandle = <0x110>;
	};

	video-codec@ff650000 {
		compatible = "rockchip,rk3399-vpu";
		reg = <0x0 0xff650000 0x0 0x800>;
		interrupts = <0x0 0x72 0x4 0x0 0x0 0x71 0x4 0x0>;
		interrupt-names = "vepu", "vdpu";
		clocks = <0x8 0xeb 0x8 0x1ea>;
		clock-names = "aclk", "hclk";
		iommus = <0x96>;
		power-domains = <0x1b 0x1f>;
		phandle = <0x111>;
	};

	iommu@ff650800 {
		compatible = "rockchip,iommu";
		reg = <0x0 0xff650800 0x0 0x40>;
		interrupts = <0x0 0x73 0x4 0x0>;
		interrupt-names = "vpu_mmu";
		clocks = <0x8 0xeb 0x8 0x1ea>;
		clock-names = "aclk", "iface";
		#iommu-cells = <0x0>;
		power-domains = <0x1b 0x1f>;
		phandle = <0x96>;
	};

	video-codec@ff660000 {
		compatible = "rockchip,rk3399-vdec";
		reg = <0x0 0xff660000 0x0 0x400>;
		interrupts = <0x0 0x74 0x4 0x0>;
		clocks = <0x8 0xed 0x8 0x1ec 0x8 0x9f 0x8 0x9e>;
		clock-names = "axi", "ahb", "cabac", "core";
		iommus = <0x97>;
		power-domains = <0x1b 0x20>;
		phandle = <0x112>;
	};

	iommu@ff660480 {
		compatible = "rockchip,iommu";
		reg = <0x0 0xff660480 0x0 0x40 0x0 0xff6604c0 0x0 0x40>;
		interrupts = <0x0 0x75 0x4 0x0>;
		interrupt-names = "vdec_mmu";
		clocks = <0x8 0xed 0x8 0x1ec>;
		clock-names = "aclk", "iface";
		power-domains = <0x1b 0x20>;
		#iommu-cells = <0x0>;
		phandle = <0x97>;
	};

	iommu@ff670800 {
		compatible = "rockchip,iommu";
		reg = <0x0 0xff670800 0x0 0x40>;
		interrupts = <0x0 0x2a 0x4 0x0>;
		interrupt-names = "iep_mmu";
		clocks = <0x8 0xe1 0x8 0x1dd>;
		clock-names = "aclk", "iface";
		#iommu-cells = <0x0>;
		status = "disabled";
		phandle = <0x113>;
	};

	rga@ff680000 {
		compatible = "rockchip,rk3399-rga";
		reg = <0x0 0xff680000 0x0 0x10000>;
		interrupts = <0x0 0x37 0x4 0x0>;
		clocks = <0x8 0xdc 0x8 0x1e5 0x8 0x6d>;
		clock-names = "aclk", "hclk", "sclk";
		resets = <0x8 0x6a 0x8 0x67 0x8 0x69>;
		reset-names = "core", "axi", "ahb";
		power-domains = <0x1b 0x21>;
		phandle = <0x114>;
	};

	efuse@ff690000 {
		compatible = "rockchip,rk3399-efuse";
		reg = <0x0 0xff690000 0x0 0x80>;
		#address-cells = <0x1>;
		#size-cells = <0x1>;
		clocks = <0x8 0x17d>;
		clock-names = "pclk_efuse";
		phandle = <0x115>;

		cpu-id@7 {
			reg = <0x7 0x10>;
			phandle = <0x116>;
		};

		cpu-leakage@17 {
			reg = <0x17 0x1>;
			phandle = <0x117>;
		};

		gpu-leakage@18 {
			reg = <0x18 0x1>;
			phandle = <0x118>;
		};

		center-leakage@19 {
			reg = <0x19 0x1>;
			phandle = <0x119>;
		};

		cpu-leakage@1a {
			reg = <0x1a 0x1>;
			phandle = <0x11a>;
		};

		logic-leakage@1b {
			reg = <0x1b 0x1>;
			phandle = <0x11b>;
		};

		wafer-info@1c {
			reg = <0x1c 0x1>;
			phandle = <0x11c>;
		};
	};

	pmu-clock-controller@ff750000 {
		compatible = "rockchip,rk3399-pmucru";
		reg = <0x0 0xff750000 0x0 0x1000>;
		rockchip,grf = <0x98>;
		#clock-cells = <0x1>;
		#reset-cells = <0x1>;
		assigned-clocks = <0x84 0x1>;
		assigned-clock-rates = <0x284af100>;
		phandle = <0x84>;
	};

	clock-controller@ff760000 {
		compatible = "rockchip,rk3399-cru";
		reg = <0x0 0xff760000 0x0 0x1000>;
		rockchip,grf = <0x1c>;
		#clock-cells = <0x1>;
		#reset-cells = <0x1>;
		assigned-clocks = <0x8 0x5 0x8 0x4 0x8 0x6 0x8 0xc0 0x8 0x1c0 0x8 0x140 0x8 0xc2 0x8 0x1c1 0x8 0x142 0x8 0xc9 0x8 0x1c2 0x8 0x143 0x8 0xe3 0x8 0xde 0x8 0x106 0x8 0x178>;
		assigned-clock-rates = <0x2367b880 0x2faf0800 0x3b9aca00 0x8f0d180 0x47868c0 0x23c3460 0x5f5e100 0x5f5e100 0x2faf080 0x23c34600 0x5f5e100 0x2faf080 0x17d78400 0x17d78400 0xbebc200 0xbebc200>;
		phandle = <0x8>;
	};

	syscon@ff770000 {
		compatible = "rockchip,rk3399-grf", "syscon", "simple-mfd";
		reg = <0x0 0xff770000 0x0 0x10000>;
		#address-cells = <0x1>;
		#size-cells = <0x1>;
		phandle = <0x1c>;

		io-domains {
			compatible = "rockchip,rk3399-io-voltage-domain";
			status = "okay";
			audio-supply = <0x99>;
			bt656-supply = <0x83>;
			gpio1830-supply = <0x83>;
			sdmmc-supply = <0x2b>;
			phandle = <0x11d>;
		};

		mipi-dphy-rx0 {
			compatible = "rockchip,rk3399-mipi-dphy-rx0";
			clocks = <0x8 0x77 0x8 0xa5 0x8 0x16f>;
			clock-names = "dphy-ref", "dphy-cfg", "grf";
			power-domains = <0x1b 0xf>;
			#phy-cells = <0x0>;
			status = "disabled";
			phandle = <0x11e>;
		};

		usb2-phy@e450 {
			compatible = "rockchip,rk3399-usb2phy";
			reg = <0xe450 0x10>;
			clocks = <0x8 0x7b>;
			clock-names = "phyclk";
			#clock-cells = <0x0>;
			clock-output-names = "clk_usbphy0_480m";
			status = "okay";
			phandle = <0x2d>;

			host-port {
				#phy-cells = <0x0>;
				interrupts = <0x0 0x1b 0x4 0x0>;
				interrupt-names = "linestate";
				status = "okay";
				phy-supply = <0x9a>;
				phandle = <0x2e>;
			};

			otg-port {
				#phy-cells = <0x0>;
				interrupts = <0x0 0x67 0x4 0x0 0x0 0x68 0x4 0x0 0x0 0x6a 0x4 0x0>;
				interrupt-names = "otg-bvalid", "otg-id", "linestate";
				status = "okay";
				phy-supply = <0x43>;
				phandle = <0x31>;
			};
		};

		usb2-phy@e460 {
			compatible = "rockchip,rk3399-usb2phy";
			reg = <0xe460 0x10>;
			clocks = <0x8 0x7c>;
			clock-names = "phyclk";
			#clock-cells = <0x0>;
			clock-output-names = "clk_usbphy1_480m";
			status = "okay";
			phandle = <0x2f>;

			host-port {
				#phy-cells = <0x0>;
				interrupts = <0x0 0x1f 0x4 0x0>;
				interrupt-names = "linestate";
				status = "okay";
				phy-supply = <0x9a>;
				phandle = <0x30>;
			};

			otg-port {
				#phy-cells = <0x0>;
				interrupts = <0x0 0x6c 0x4 0x0 0x0 0x6d 0x4 0x0 0x0 0x6f 0x4 0x0>;
				interrupt-names = "otg-bvalid", "otg-id", "linestate";
				status = "okay";
				phy-supply = <0x90>;
				phandle = <0x33>;
			};
		};

		phy@f780 {
			compatible = "rockchip,rk3399-emmc-phy";
			reg = <0xf780 0x24>;
			clocks = <0x9b>;
			clock-names = "emmcclk";
			#phy-cells = <0x0>;
			status = "okay";
			phandle = <0x2c>;
		};

		pcie-phy {
			compatible = "rockchip,rk3399-pcie-phy";
			clocks = <0x8 0x8a>;
			clock-names = "refclk";
			#phy-cells = <0x1>;
			resets = <0x8 0x87>;
			drive-impedance-ohm = <0x32>;
			reset-names = "phy";
			status = "okay";
			phandle = <0x15>;
		};
	};

	phy@ff7c0000 {
		compatible = "rockchip,rk3399-typec-phy";
		reg = <0x0 0xff7c0000 0x0 0x40000>;
		clocks = <0x8 0x7e 0x8 0x7d>;
		clock-names = "tcpdcore", "tcpdphy-ref";
		assigned-clocks = <0x8 0x7e>;
		assigned-clock-rates = <0x2faf080>;
		power-domains = <0x1b 0x8>;
		resets = <0x8 0x95 0x8 0x94 0x8 0x14c>;
		reset-names = "uphy", "uphy-pipe", "uphy-tcphy";
		rockchip,grf = <0x1c>;
		status = "okay";
		phandle = <0x11f>;

		dp-port {
			#phy-cells = <0x0>;
			phandle = <0x35>;
		};

		usb3-port {
			#phy-cells = <0x0>;
			phandle = <0x32>;
		};
	};

	phy@ff800000 {
		compatible = "rockchip,rk3399-typec-phy";
		reg = <0x0 0xff800000 0x0 0x40000>;
		clocks = <0x8 0x80 0x8 0x7f>;
		clock-names = "tcpdcore", "tcpdphy-ref";
		assigned-clocks = <0x8 0x80>;
		assigned-clock-rates = <0x2faf080>;
		power-domains = <0x1b 0x9>;
		resets = <0x8 0x9d 0x8 0x9c 0x8 0x14d>;
		reset-names = "uphy", "uphy-pipe", "uphy-tcphy";
		rockchip,grf = <0x1c>;
		status = "okay";
		phandle = <0x120>;

		dp-port {
			#phy-cells = <0x0>;
			phandle = <0x36>;
		};

		usb3-port {
			#phy-cells = <0x0>;
			phandle = <0x34>;
		};
	};

	watchdog@ff848000 {
		compatible = "snps,dw-wdt";
		reg = <0x0 0xff848000 0x0 0x100>;
		clocks = <0x8 0x17c>;
		interrupts = <0x0 0x78 0x4 0x0>;
	};

	rktimer@ff850000 {
		compatible = "rockchip,rk3399-timer";
		reg = <0x0 0xff850000 0x0 0x1000>;
		interrupts = <0x0 0x51 0x4 0x0>;
		clocks = <0x8 0x168 0x8 0x5a>;
		clock-names = "pclk", "timer";
		phandle = <0x121>;
	};

	spdif@ff870000 {
		compatible = "rockchip,rk3399-spdif";
		reg = <0x0 0xff870000 0x0 0x1000>;
		interrupts = <0x0 0x42 0x4 0x0>;
		dmas = <0x62 0x7>;
		dma-names = "tx";
		clock-names = "mclk", "hclk";
		clocks = <0x8 0x55 0x8 0x1d7>;
		pinctrl-names = "default";
		pinctrl-0 = <0x9c>;
		power-domains = <0x1b 0x1c>;
		#sound-dai-cells = <0x0>;
		status = "disabled";
		phandle = <0x122>;
	};

	i2s@ff880000 {
		compatible = "rockchip,rk3399-i2s", "rockchip,rk3066-i2s";
		reg = <0x0 0xff880000 0x0 0x1000>;
		rockchip,grf = <0x1c>;
		interrupts = <0x0 0x27 0x4 0x0>;
		dmas = <0x62 0x0 0x62 0x1>;
		dma-names = "tx", "rx";
		clock-names = "i2s_clk", "i2s_hclk";
		clocks = <0x8 0x56 0x8 0x1d4>;
		pinctrl-names = "default";
		pinctrl-0 = <0x9d>;
		power-domains = <0x1b 0x1c>;
		#sound-dai-cells = <0x0>;
		status = "okay";
		rockchip,playback-channels = <0x8>;
		rockchip,capture-channels = <0x8>;
		phandle = <0x123>;
	};

	i2s@ff890000 {
		compatible = "rockchip,rk3399-i2s", "rockchip,rk3066-i2s";
		reg = <0x0 0xff890000 0x0 0x1000>;
		interrupts = <0x0 0x28 0x4 0x0>;
		dmas = <0x62 0x2 0x62 0x3>;
		dma-names = "tx", "rx";
		clock-names = "i2s_clk", "i2s_hclk";
		clocks = <0x8 0x57 0x8 0x1d5>;
		pinctrl-names = "default";
		pinctrl-0 = <0x9e>;
		power-domains = <0x1b 0x1c>;
		#sound-dai-cells = <0x0>;
		status = "okay";
		rockchip,playback-channels = <0x2>;
		rockchip,capture-channels = <0x2>;
		phandle = <0xd2>;
	};

	i2s@ff8a0000 {
		compatible = "rockchip,rk3399-i2s", "rockchip,rk3066-i2s";
		reg = <0x0 0xff8a0000 0x0 0x1000>;
		interrupts = <0x0 0x29 0x4 0x0>;
		dmas = <0x62 0x4 0x62 0x5>;
		dma-names = "tx", "rx";
		clock-names = "i2s_clk", "i2s_hclk";
		clocks = <0x8 0x58 0x8 0x1d6>;
		power-domains = <0x1b 0x1c>;
		#sound-dai-cells = <0x0>;
		status = "okay";
		phandle = <0xab>;
	};

	vop@ff8f0000 {
		compatible = "rockchip,rk3399-vop-lit";
		reg = <0x0 0xff8f0000 0x0 0x3efc>;
		interrupts = <0x0 0x77 0x4 0x0>;
		assigned-clocks = <0x8 0xdb 0x8 0x1db>;
		assigned-clock-rates = <0x17d78400 0x5f5e100>;
		clocks = <0x8 0xdb 0x8 0xb5 0x8 0x1db>;
		clock-names = "aclk_vop", "dclk_vop", "hclk_vop";
		iommus = <0x9f>;
		power-domains = <0x1b 0x12>;
		resets = <0x8 0x113 0x8 0x117 0x8 0x119>;
		reset-names = "axi", "ahb", "dclk";
		status = "okay";
		phandle = <0x124>;

		port {
			#address-cells = <0x1>;
			#size-cells = <0x0>;
			phandle = <0xf>;

			endpoint@0 {
				reg = <0x0>;
				remote-endpoint = <0xa0>;
				phandle = <0xb2>;
			};

			endpoint@1 {
				reg = <0x1>;
				remote-endpoint = <0xa1>;
				phandle = <0xb7>;
			};

			endpoint@2 {
				reg = <0x2>;
				remote-endpoint = <0xa2>;
				phandle = <0xb0>;
			};

			endpoint@3 {
				reg = <0x3>;
				remote-endpoint = <0xa3>;
				phandle = <0xb4>;
			};

			endpoint@4 {
				reg = <0x4>;
				remote-endpoint = <0xa4>;
				phandle = <0x38>;
			};
		};
	};

	iommu@ff8f3f00 {
		compatible = "rockchip,iommu";
		reg = <0x0 0xff8f3f00 0x0 0x100>;
		interrupts = <0x0 0x77 0x4 0x0>;
		interrupt-names = "vopl_mmu";
		clocks = <0x8 0xdb 0x8 0x1db>;
		clock-names = "aclk", "iface";
		power-domains = <0x1b 0x12>;
		#iommu-cells = <0x0>;
		status = "okay";
		phandle = <0x9f>;
	};

	vop@ff900000 {
		compatible = "rockchip,rk3399-vop-big";
		reg = <0x0 0xff900000 0x0 0x3efc>;
		interrupts = <0x0 0x76 0x4 0x0>;
		assigned-clocks = <0x8 0xd9 0x8 0x1d9>;
		assigned-clock-rates = <0x17d78400 0x5f5e100>;
		clocks = <0x8 0xd9 0x8 0xb4 0x8 0x1d9>;
		clock-names = "aclk_vop", "dclk_vop", "hclk_vop";
		iommus = <0xa5>;
		power-domains = <0x1b 0x11>;
		resets = <0x8 0x112 0x8 0x116 0x8 0x118>;
		reset-names = "axi", "ahb", "dclk";
		status = "okay";
		phandle = <0x125>;

		port {
			#address-cells = <0x1>;
			#size-cells = <0x0>;
			phandle = <0x10>;

			endpoint@0 {
				reg = <0x0>;
				remote-endpoint = <0xa6>;
				phandle = <0xb6>;
			};

			endpoint@1 {
				reg = <0x1>;
				remote-endpoint = <0xa7>;
				phandle = <0xb1>;
			};

			endpoint@2 {
				reg = <0x2>;
				remote-endpoint = <0xa8>;
				phandle = <0xaf>;
			};

			endpoint@3 {
				reg = <0x3>;
				remote-endpoint = <0xa9>;
				phandle = <0xb3>;
			};

			endpoint@4 {
				reg = <0x4>;
				remote-endpoint = <0xaa>;
				phandle = <0x37>;
			};
		};
	};

	iommu@ff903f00 {
		compatible = "rockchip,iommu";
		reg = <0x0 0xff903f00 0x0 0x100>;
		interrupts = <0x0 0x76 0x4 0x0>;
		interrupt-names = "vopb_mmu";
		clocks = <0x8 0xd9 0x8 0x1d9>;
		clock-names = "aclk", "iface";
		power-domains = <0x1b 0x11>;
		#iommu-cells = <0x0>;
		status = "okay";
		phandle = <0xa5>;
	};

	iommu@ff914000 {
		compatible = "rockchip,iommu";
		reg = <0x0 0xff914000 0x0 0x100 0x0 0xff915000 0x0 0x100>;
		interrupts = <0x0 0x2b 0x4 0x0>;
		interrupt-names = "isp0_mmu";
		clocks = <0x8 0xe9 0x8 0x1e3>;
		clock-names = "aclk", "iface";
		#iommu-cells = <0x0>;
		power-domains = <0x1b 0x13>;
		rockchip,disable-mmu-reset;
		phandle = <0x126>;
	};

	iommu@ff924000 {
		compatible = "rockchip,iommu";
		reg = <0x0 0xff924000 0x0 0x100 0x0 0xff925000 0x0 0x100>;
		interrupts = <0x0 0x2c 0x4 0x0>;
		interrupt-names = "isp1_mmu";
		clocks = <0x8 0xea 0x8 0x1e4>;
		clock-names = "aclk", "iface";
		#iommu-cells = <0x0>;
		power-domains = <0x1b 0x14>;
		rockchip,disable-mmu-reset;
		phandle = <0x127>;
	};

	hdmi-sound {
		compatible = "simple-audio-card";
		simple-audio-card,format = "i2s";
		simple-audio-card,mclk-fs = <0x100>;
		simple-audio-card,name = "hdmi-sound";
		status = "okay";
		phandle = <0x128>;

		simple-audio-card,cpu {
			sound-dai = <0xab>;
		};

		simple-audio-card,codec {
			sound-dai = <0xac>;
		};
	};

	hdmi@ff940000 {
		compatible = "rockchip,rk3399-dw-hdmi";
		reg = <0x0 0xff940000 0x0 0x20000>;
		interrupts = <0x0 0x17 0x4 0x0>;
		clocks = <0x8 0x174 0x8 0x71 0x8 0x7 0x8 0x16f 0x8 0x70>;
		clock-names = "iahb", "isfr", "vpll", "grf", "cec";
		power-domains = <0x1b 0x15>;
		reg-io-width = <0x4>;
		rockchip,grf = <0x1c>;
		#sound-dai-cells = <0x0>;
		status = "okay";
		ddc-i2c-bus = <0xad>;
		pinctrl-names = "default";
		pinctrl-0 = <0xae>;
		phandle = <0xac>;

		ports {

			port {
				#address-cells = <0x1>;
				#size-cells = <0x0>;
				phandle = <0x129>;

				endpoint@0 {
					reg = <0x0>;
					remote-endpoint = <0xaf>;
					phandle = <0xa8>;
				};

				endpoint@1 {
					reg = <0x1>;
					remote-endpoint = <0xb0>;
					phandle = <0xa2>;
				};
			};
		};
	};

	mipi@ff960000 {
		compatible = "rockchip,rk3399-mipi-dsi", "snps,dw-mipi-dsi";
		reg = <0x0 0xff960000 0x0 0x8000>;
		interrupts = <0x0 0x2d 0x4 0x0>;
		clocks = <0x8 0xa2 0x8 0x170 0x8 0xa3 0x8 0x16f>;
		clock-names = "ref", "pclk", "phy_cfg", "grf";
		power-domains = <0x1b 0xf>;
		resets = <0x8 0xfb>;
		reset-names = "apb";
		rockchip,grf = <0x1c>;
		#address-cells = <0x1>;
		#size-cells = <0x0>;
		status = "disabled";
		phandle = <0x12a>;

		ports {
			#address-cells = <0x1>;
			#size-cells = <0x0>;

			port@0 {
				reg = <0x0>;
				#address-cells = <0x1>;
				#size-cells = <0x0>;
				phandle = <0x12b>;

				endpoint@0 {
					reg = <0x0>;
					remote-endpoint = <0xb1>;
					phandle = <0xa7>;
				};

				endpoint@1 {
					reg = <0x1>;
					remote-endpoint = <0xb2>;
					phandle = <0xa0>;
				};
			};
		};
	};

	mipi@ff968000 {
		compatible = "rockchip,rk3399-mipi-dsi", "snps,dw-mipi-dsi";
		reg = <0x0 0xff968000 0x0 0x8000>;
		interrupts = <0x0 0x2e 0x4 0x0>;
		clocks = <0x8 0xa2 0x8 0x171 0x8 0xa4 0x8 0x16f>;
		clock-names = "ref", "pclk", "phy_cfg", "grf";
		power-domains = <0x1b 0xf>;
		resets = <0x8 0xfc>;
		reset-names = "apb";
		rockchip,grf = <0x1c>;
		#address-cells = <0x1>;
		#size-cells = <0x0>;
		status = "disabled";
		phandle = <0x12c>;

		ports {
			#address-cells = <0x1>;
			#size-cells = <0x0>;

			port@0 {
				reg = <0x0>;
				#address-cells = <0x1>;
				#size-cells = <0x0>;
				phandle = <0x12d>;

				endpoint@0 {
					reg = <0x0>;
					remote-endpoint = <0xb3>;
					phandle = <0xa9>;
				};

				endpoint@1 {
					reg = <0x1>;
					remote-endpoint = <0xb4>;
					phandle = <0xa3>;
				};
			};
		};
	};

	edp@ff970000 {
		compatible = "rockchip,rk3399-edp";
		reg = <0x0 0xff970000 0x0 0x8000>;
		interrupts = <0x0 0xa 0x4 0x0>;
		clocks = <0x8 0x16a 0x8 0x16c 0x8 0x16f>;
		clock-names = "dp", "pclk", "grf";
		pinctrl-names = "default";
		pinctrl-0 = <0xb5>;
		power-domains = <0x1b 0x19>;
		resets = <0x8 0x11d>;
		reset-names = "dp";
		rockchip,grf = <0x1c>;
		status = "disabled";
		phandle = <0x12e>;

		ports {
			#address-cells = <0x1>;
			#size-cells = <0x0>;

			port@0 {
				reg = <0x0>;
				#address-cells = <0x1>;
				#size-cells = <0x0>;
				phandle = <0x12f>;

				endpoint@0 {
					reg = <0x0>;
					remote-endpoint = <0xb6>;
					phandle = <0xa6>;
				};

				endpoint@1 {
					reg = <0x1>;
					remote-endpoint = <0xb7>;
					phandle = <0xa1>;
				};
			};
		};
	};

	gpu@ff9a0000 {
		compatible = "rockchip,rk3399-mali", "arm,mali-t860";
		reg = <0x0 0xff9a0000 0x0 0x10000>;
		interrupts = <0x0 0x14 0x4 0x0 0x0 0x15 0x4 0x0 0x0 0x13 0x4 0x0>;
		interrupt-names = "job", "mmu", "gpu";
		clocks = <0x8 0xd0>;
		#cooling-cells = <0x2>;
		power-domains = <0x1b 0x23>;
		status = "okay";
		operating-points-v2 = <0xb8>;
		mali-supply = <0xb9>;
		phandle = <0x6b>;
	};

	pinctrl {
		compatible = "rockchip,rk3399-pinctrl";
		rockchip,grf = <0x1c>;
		rockchip,pmu = <0x98>;
		#address-cells = <0x2>;
		#size-cells = <0x2>;
		ranges;
		phandle = <0x130>;

		gpio0@ff720000 {
			compatible = "rockchip,gpio-bank";
			reg = <0x0 0xff720000 0x0 0x100>;
			clocks = <0x84 0x17>;
			interrupts = <0x0 0xe 0x4 0x0>;
			gpio-controller;
			#gpio-cells = <0x2>;
			interrupt-controller;
			#interrupt-cells = <0x2>;
			phandle = <0x25>;
		};

		gpio1@ff730000 {
			compatible = "rockchip,gpio-bank";
			reg = <0x0 0xff730000 0x0 0x100>;
			clocks = <0x84 0x18>;
			interrupts = <0x0 0xf 0x4 0x0>;
			gpio-controller;
			#gpio-cells = <0x2>;
			interrupt-controller;
			#interrupt-cells = <0x2>;
			phandle = <0x41>;
		};

		gpio2@ff780000 {
			compatible = "rockchip,gpio-bank";
			reg = <0x0 0xff780000 0x0 0x100>;
			clocks = <0x8 0x150>;
			interrupts = <0x0 0x10 0x4 0x0>;
			gpio-controller;
			#gpio-cells = <0x2>;
			interrupt-controller;
			#interrupt-cells = <0x2>;
			phandle = <0x48>;
		};

		gpio3@ff788000 {
			compatible = "rockchip,gpio-bank";
			reg = <0x0 0xff788000 0x0 0x100>;
			clocks = <0x8 0x151>;
			interrupts = <0x0 0x11 0x4 0x0>;
			gpio-controller;
			#gpio-cells = <0x2>;
			interrupt-controller;
			#interrupt-cells = <0x2>;
			phandle = <0x20>;
		};

		gpio4@ff790000 {
			compatible = "rockchip,gpio-bank";
			reg = <0x0 0xff790000 0x0 0x100>;
			clocks = <0x8 0x152>;
			interrupts = <0x0 0x12 0x4 0x0>;
			gpio-controller;
			#gpio-cells = <0x2>;
			interrupt-controller;
			#interrupt-cells = <0x2>;
			phandle = <0x16>;
		};

		pcfg-pull-up {
			bias-pull-up;
			phandle = <0xbd>;
		};

		pcfg-pull-down {
			bias-pull-down;
			phandle = <0xbf>;
		};

		pcfg-pull-none {
			bias-disable;
			phandle = <0xba>;
		};

		pcfg-pull-none-12ma {
			bias-disable;
			drive-strength = <0xc>;
			phandle = <0xbc>;
		};

		pcfg-pull-none-13ma {
			bias-disable;
			drive-strength = <0xd>;
			phandle = <0xbb>;
		};

		pcfg-pull-none-18ma {
			bias-disable;
			drive-strength = <0x12>;
			phandle = <0x131>;
		};

		pcfg-pull-none-20ma {
			bias-disable;
			drive-strength = <0x14>;
			phandle = <0x132>;
		};

		pcfg-pull-up-2ma {
			bias-pull-up;
			drive-strength = <0x2>;
			phandle = <0x133>;
		};

		pcfg-pull-up-8ma {
			bias-pull-up;
			drive-strength = <0x8>;
			phandle = <0xbe>;
		};

		pcfg-pull-up-18ma {
			bias-pull-up;
			drive-strength = <0x12>;
			phandle = <0x134>;
		};

		pcfg-pull-up-20ma {
			bias-pull-up;
			drive-strength = <0x14>;
			phandle = <0x135>;
		};

		pcfg-pull-down-4ma {
			bias-pull-down;
			drive-strength = <0x4>;
			phandle = <0x136>;
		};

		pcfg-pull-down-8ma {
			bias-pull-down;
			drive-strength = <0x8>;
			phandle = <0x137>;
		};

		pcfg-pull-down-12ma {
			bias-pull-down;
			drive-strength = <0xc>;
			phandle = <0x138>;
		};

		pcfg-pull-down-18ma {
			bias-pull-down;
			drive-strength = <0x12>;
			phandle = <0x139>;
		};

		pcfg-pull-down-20ma {
			bias-pull-down;
			drive-strength = <0x14>;
			phandle = <0x13a>;
		};

		pcfg-output-high {
			output-high;
			phandle = <0xc0>;
		};

		pcfg-output-low {
			output-low;
			phandle = <0x13b>;
		};

		clock {

			clk-32k {
				rockchip,pins = <0x0 0x0 0x2 0xba>;
				phandle = <0x13c>;
			};
		};

		edp {

			edp-hpd {
				rockchip,pins = <0x4 0x17 0x2 0xba>;
				phandle = <0xb5>;
			};
		};

		gmac {

			rgmii-pins {
				rockchip,pins = <0x3 0x11 0x1 0xbb 0x3 0xe 0x1 0xba 0x3 0xd 0x1 0xba 0x3 0xc 0x1 0xbb 0x3 0xb 0x1 0xba 0x3 0x9 0x1 0xba 0x3 0x8 0x1 0xba 0x3 0x7 0x1 0xba 0x3 0x6 0x1 0xba 0x3 0x5 0x1 0xbb 0x3 0x4 0x1 0xbb 0x3 0x3 0x1 0xba 0x3 0x2 0x1 0xba 0x3 0x1 0x1 0xbb 0x3 0x0 0x1 0xbb>;
				phandle = <0x1f>;
			};

			rmii-pins {
				rockchip,pins = <0x3 0xd 0x1 0xba 0x3 0xc 0x1 0xbb 0x3 0xb 0x1 0xba 0x3 0xa 0x1 0xba 0x3 0x9 0x1 0xba 0x3 0x8 0x1 0xba 0x3 0x7 0x1 0xba 0x3 0x6 0x1 0xba 0x3 0x5 0x1 0xbb 0x3 0x4 0x1 0xbb>;
				phandle = <0x13d>;
			};
		};

		i2c0 {

			i2c0-xfer {
				rockchip,pins = <0x1 0xf 0x2 0xba 0x1 0x10 0x2 0xba>;
				phandle = <0x8a>;
			};
		};

		i2c1 {

			i2c1-xfer {
				rockchip,pins = <0x4 0x2 0x1 0xba 0x4 0x1 0x1 0xba>;
				phandle = <0x3a>;
			};
		};

		i2c2 {

			i2c2-xfer {
				rockchip,pins = <0x2 0x1 0x2 0xbc 0x2 0x0 0x2 0xbc>;
				phandle = <0x3c>;
			};
		};

		i2c3 {

			i2c3-xfer {
				rockchip,pins = <0x4 0x11 0x1 0xba 0x4 0x10 0x1 0xba>;
				phandle = <0x3d>;
			};
		};

		i2c4 {

			i2c4-xfer {
				rockchip,pins = <0x1 0xc 0x1 0xba 0x1 0xb 0x1 0xba>;
				phandle = <0x8e>;
			};
		};

		i2c5 {

			i2c5-xfer {
				rockchip,pins = <0x3 0xb 0x2 0xba 0x3 0xa 0x2 0xba>;
				phandle = <0x3e>;
			};
		};

		i2c6 {

			i2c6-xfer {
				rockchip,pins = <0x2 0xa 0x2 0xba 0x2 0x9 0x2 0xba>;
				phandle = <0x3f>;
			};
		};

		i2c7 {

			i2c7-xfer {
				rockchip,pins = <0x2 0x8 0x2 0xba 0x2 0x7 0x2 0xba>;
				phandle = <0x40>;
			};
		};

		i2c8 {

			i2c8-xfer {
				rockchip,pins = <0x1 0x15 0x1 0xba 0x1 0x14 0x1 0xba>;
				phandle = <0x91>;
			};
		};

		i2s0 {

			i2s0-2ch-bus {
				rockchip,pins = <0x3 0x18 0x1 0xba 0x3 0x19 0x1 0xba 0x3 0x1a 0x1 0xba 0x3 0x1b 0x1 0xba 0x3 0x1f 0x1 0xba 0x4 0x0 0x1 0xba>;
				phandle = <0x13e>;
			};

			i2s0-8ch-bus {
				rockchip,pins = <0x3 0x18 0x1 0xba 0x3 0x19 0x1 0xba 0x3 0x1a 0x1 0xba 0x3 0x1b 0x1 0xba 0x3 0x1c 0x1 0xba 0x3 0x1d 0x1 0xba 0x3 0x1e 0x1 0xba 0x3 0x1f 0x1 0xba 0x4 0x0 0x1 0xba>;
				phandle = <0x9d>;
			};
		};

		i2s1 {

			i2s1-2ch-bus {
				rockchip,pins = <0x4 0x3 0x1 0xba 0x4 0x4 0x1 0xba 0x4 0x5 0x1 0xba 0x4 0x6 0x1 0xba 0x4 0x7 0x1 0xba>;
				phandle = <0x9e>;
			};
		};

		sdio0 {

			sdio0-bus1 {
				rockchip,pins = <0x2 0x14 0x1 0xbd>;
				phandle = <0x13f>;
			};

			sdio0-bus4 {
				rockchip,pins = <0x2 0x14 0x1 0xbd 0x2 0x15 0x1 0xbd 0x2 0x16 0x1 0xbd 0x2 0x17 0x1 0xbd>;
				phandle = <0x22>;
			};

			sdio0-cmd {
				rockchip,pins = <0x2 0x18 0x1 0xbd>;
				phandle = <0x23>;
			};

			sdio0-clk {
				rockchip,pins = <0x2 0x19 0x1 0xba>;
				phandle = <0x24>;
			};

			sdio0-cd {
				rockchip,pins = <0x2 0x1a 0x1 0xbd>;
				phandle = <0x140>;
			};

			sdio0-pwr {
				rockchip,pins = <0x2 0x1b 0x1 0xbd>;
				phandle = <0x141>;
			};

			sdio0-bkpwr {
				rockchip,pins = <0x2 0x1c 0x1 0xbd>;
				phandle = <0x142>;
			};

			sdio0-wp {
				rockchip,pins = <0x0 0x3 0x1 0xbd>;
				phandle = <0x143>;
			};

			sdio0-int {
				rockchip,pins = <0x0 0x4 0x1 0xbd>;
				phandle = <0x144>;
			};
		};

		sdmmc {

			sdmmc-bus1 {
				rockchip,pins = <0x4 0x8 0x1 0xbe>;
				phandle = <0x145>;
			};

			sdmmc-bus4 {
				rockchip,pins = <0x4 0x8 0x1 0xbe 0x4 0x9 0x1 0xbe 0x4 0xa 0x1 0xbe 0x4 0xb 0x1 0xbe>;
				phandle = <0x29>;
			};

			sdmmc-clk {
				rockchip,pins = <0x4 0xc 0x1 0xbc>;
				phandle = <0x27>;
			};

			sdmmc-cmd {
				rockchip,pins = <0x4 0xd 0x1 0xbe>;
				phandle = <0x28>;
			};

			sdmmc-cd {
				rockchip,pins = <0x0 0x7 0x1 0xbd>;
				phandle = <0x146>;
			};

			sdmmc-wp {
				rockchip,pins = <0x0 0x8 0x1 0xbe>;
				phandle = <0x147>;
			};

			vcc3v0-sd-en {
				rockchip,pins = <0x4 0x1e 0x0 0xba>;
				phandle = <0xc8>;
			};
		};

		suspend {

			ap-pwroff {
				rockchip,pins = <0x1 0x5 0x1 0xba>;
				phandle = <0x148>;
			};

			ddrio-pwroff {
				rockchip,pins = <0x0 0x1 0x1 0xba>;
				phandle = <0x149>;
			};
		};

		spdif {

			spdif-bus {
				rockchip,pins = <0x4 0x15 0x1 0xba>;
				phandle = <0x9c>;
			};

			spdif-bus-1 {
				rockchip,pins = <0x3 0x10 0x3 0xba>;
				phandle = <0x14a>;
			};
		};

		spi0 {

			spi0-clk {
				rockchip,pins = <0x3 0x6 0x2 0xbd>;
				phandle = <0x52>;
			};

			spi0-cs0 {
				rockchip,pins = <0x3 0x7 0x2 0xbd>;
				phandle = <0x55>;
			};

			spi0-cs1 {
				rockchip,pins = <0x3 0x8 0x2 0xbd>;
				phandle = <0x14b>;
			};

			spi0-tx {
				rockchip,pins = <0x3 0x5 0x2 0xbd>;
				phandle = <0x53>;
			};

			spi0-rx {
				rockchip,pins = <0x3 0x4 0x2 0xbd>;
				phandle = <0x54>;
			};
		};

		spi1 {

			spi1-clk {
				rockchip,pins = <0x1 0x9 0x2 0xbd>;
				phandle = <0x56>;
			};

			spi1-cs0 {
				rockchip,pins = <0x1 0xa 0x2 0xbd>;
				phandle = <0x59>;
			};

			spi1-rx {
				rockchip,pins = <0x1 0x7 0x2 0xbd>;
				phandle = <0x58>;
			};

			spi1-tx {
				rockchip,pins = <0x1 0x8 0x2 0xbd>;
				phandle = <0x57>;
			};
		};

		spi2 {

			spi2-clk {
				rockchip,pins = <0x2 0xb 0x1 0xbd>;
				phandle = <0x5a>;
			};

			spi2-cs0 {
				rockchip,pins = <0x2 0xc 0x1 0xbd>;
				phandle = <0x5d>;
			};

			spi2-rx {
				rockchip,pins = <0x2 0x9 0x1 0xbd>;
				phandle = <0x5c>;
			};

			spi2-tx {
				rockchip,pins = <0x2 0xa 0x1 0xbd>;
				phandle = <0x5b>;
			};
		};

		spi3 {

			spi3-clk {
				rockchip,pins = <0x1 0x11 0x1 0xbd>;
				phandle = <0x85>;
			};

			spi3-cs0 {
				rockchip,pins = <0x1 0x12 0x1 0xbd>;
				phandle = <0x88>;
			};

			spi3-rx {
				rockchip,pins = <0x1 0xf 0x1 0xbd>;
				phandle = <0x87>;
			};

			spi3-tx {
				rockchip,pins = <0x1 0x10 0x1 0xbd>;
				phandle = <0x86>;
			};
		};

		spi4 {

			spi4-clk {
				rockchip,pins = <0x3 0x2 0x2 0xbd>;
				phandle = <0x5e>;
			};

			spi4-cs0 {
				rockchip,pins = <0x3 0x3 0x2 0xbd>;
				phandle = <0x61>;
			};

			spi4-rx {
				rockchip,pins = <0x3 0x0 0x2 0xbd>;
				phandle = <0x60>;
			};

			spi4-tx {
				rockchip,pins = <0x3 0x1 0x2 0xbd>;
				phandle = <0x5f>;
			};
		};

		spi5 {

			spi5-clk {
				rockchip,pins = <0x2 0x16 0x2 0xbd>;
				phandle = <0x63>;
			};

			spi5-cs0 {
				rockchip,pins = <0x2 0x17 0x2 0xbd>;
				phandle = <0x66>;
			};

			spi5-rx {
				rockchip,pins = <0x2 0x14 0x2 0xbd>;
				phandle = <0x65>;
			};

			spi5-tx {
				rockchip,pins = <0x2 0x15 0x2 0xbd>;
				phandle = <0x64>;
			};
		};

		testclk {

			test-clkout0 {
				rockchip,pins = <0x0 0x0 0x1 0xba>;
				phandle = <0x14c>;
			};

			test-clkout1 {
				rockchip,pins = <0x2 0x19 0x2 0xba>;
				phandle = <0x14d>;
			};

			test-clkout2 {
				rockchip,pins = <0x0 0x8 0x3 0xba>;
				phandle = <0x14e>;
			};
		};

		tsadc {

			otp-pin {
				rockchip,pins = <0x1 0x6 0x0 0xba>;
				phandle = <0x6c>;
			};

			otp-out {
				rockchip,pins = <0x1 0x6 0x1 0xba>;
				phandle = <0x6d>;
			};
		};

		uart0 {

			uart0-xfer {
				rockchip,pins = <0x2 0x10 0x1 0xbd 0x2 0x11 0x1 0xba>;
				phandle = <0x44>;
			};

			uart0-cts {
				rockchip,pins = <0x2 0x12 0x1 0xba>;
				phandle = <0x46>;
			};

			uart0-rts {
				rockchip,pins = <0x2 0x13 0x1 0xba>;
				phandle = <0x45>;
			};
		};

		uart1 {

			uart1-xfer {
				rockchip,pins = <0x3 0xc 0x2 0xbd 0x3 0xd 0x2 0xba>;
				phandle = <0x4e>;
			};
		};

		uart2a {

			uart2a-xfer {
				rockchip,pins = <0x4 0x8 0x2 0xbd 0x4 0x9 0x2 0xba>;
				phandle = <0x14f>;
			};
		};

		uart2b {

			uart2b-xfer {
				rockchip,pins = <0x4 0x10 0x2 0xbd 0x4 0x11 0x2 0xba>;
				phandle = <0x150>;
			};
		};

		uart2c {

			uart2c-xfer {
				rockchip,pins = <0x4 0x13 0x1 0xbd 0x4 0x14 0x1 0xba>;
				phandle = <0x4f>;
			};
		};

		uart3 {

			uart3-xfer {
				rockchip,pins = <0x3 0xe 0x2 0xbd 0x3 0xf 0x2 0xba>;
				phandle = <0x50>;
			};

			uart3-cts {
				rockchip,pins = <0x3 0x10 0x2 0xba>;
				phandle = <0x151>;
			};

			uart3-rts {
				rockchip,pins = <0x3 0x11 0x2 0xba>;
				phandle = <0x152>;
			};
		};

		uart4 {

			uart4-xfer {
				rockchip,pins = <0x1 0x7 0x1 0xbd 0x1 0x8 0x1 0xba>;
				phandle = <0x89>;
			};
		};

		uarthdcp {

			uarthdcp-xfer {
				rockchip,pins = <0x4 0x15 0x2 0xbd 0x4 0x16 0x2 0xba>;
				phandle = <0x153>;
			};
		};

		pwm0 {

			pwm0-pin {
				rockchip,pins = <0x4 0x12 0x1 0xba>;
				phandle = <0x92>;
			};

			pwm0-pin-pull-down {
				rockchip,pins = <0x4 0x12 0x1 0xbf>;
				phandle = <0x154>;
			};

			vop0-pwm-pin {
				rockchip,pins = <0x4 0x12 0x2 0xba>;
				phandle = <0x155>;
			};

			vop1-pwm-pin {
				rockchip,pins = <0x4 0x12 0x3 0xba>;
				phandle = <0x156>;
			};
		};

		pwm1 {

			pwm1-pin {
				rockchip,pins = <0x4 0x16 0x1 0xba>;
				phandle = <0x93>;
			};

			pwm1-pin-pull-down {
				rockchip,pins = <0x4 0x16 0x1 0xbf>;
				phandle = <0x157>;
			};
		};

		pwm2 {

			pwm2-pin {
				rockchip,pins = <0x1 0x13 0x1 0xba>;
				phandle = <0x94>;
			};

			pwm2-pin-pull-down {
				rockchip,pins = <0x1 0x13 0x1 0xbf>;
				phandle = <0x158>;
			};
		};

		pwm3a {

			pwm3a-pin {
				rockchip,pins = <0x0 0x6 0x1 0xba>;
				phandle = <0x95>;
			};
		};

		pwm3b {

			pwm3b-pin {
				rockchip,pins = <0x1 0xe 0x1 0xba>;
				phandle = <0x159>;
			};
		};

		hdmi {

			hdmi-i2c-xfer {
				rockchip,pins = <0x4 0x11 0x3 0xba 0x4 0x10 0x3 0xba>;
				phandle = <0x15a>;
			};

			hdmi-cec {
				rockchip,pins = <0x4 0x17 0x1 0xba>;
				phandle = <0xae>;
			};
		};

		pcie {

			pci-clkreqn-cpm {
				rockchip,pins = <0x2 0x1a 0x0 0xba>;
				phandle = <0x15b>;
			};

			pci-clkreqnb-cpm {
				rockchip,pins = <0x4 0x18 0x0 0xba>;
				phandle = <0x15c>;
			};

			vcc3v3-pcie-en {
				rockchip,pins = <0x1 0x11 0x0 0xba>;
				phandle = <0xd1>;
			};

			pcie-perst {
				rockchip,pins = <0x4 0x19 0x0 0xba>;
				phandle = <0x17>;
			};

			pcie-pwr-en {
				rockchip,pins = <0x1 0x11 0x0 0xba>;
				phandle = <0x15d>;
			};

			pcie-3g-drv {
				rockchip,pins = <0x0 0x2 0x0 0xbd>;
				phandle = <0x15e>;
			};
		};

		buttons {

			pwr-key-l {
				rockchip,pins = <0x0 0x5 0x0 0xbd>;
				phandle = <0x15f>;
			};

			pwrbtn {
				rockchip,pins = <0x0 0x5 0x0 0xbd>;
				phandle = <0xc3>;
			};
		};

		lcd-panel {

			lcd-panel-reset {
				rockchip,pins = <0x4 0x1e 0x0 0xbd>;
				phandle = <0x160>;
			};
		};

		leds {

			diy-led-pin {
				rockchip,pins = <0x0 0xd 0x0 0xba>;
				phandle = <0xc5>;
			};

			work-led-pin {
				rockchip,pins = <0x2 0x1b 0x0 0xba>;
				phandle = <0xc4>;
			};

			yellow-led-pin {
				rockchip,pins = <0x0 0x2 0x0 0xba>;
				phandle = <0x161>;
			};
		};

		pmic {

			vsel1-pin {
				rockchip,pins = <0x1 0x12 0x0 0xbf>;
				phandle = <0x8c>;
			};

			vsel2-pin {
				rockchip,pins = <0x1 0xe 0x0 0xbf>;
				phandle = <0x8d>;
			};

			pmic-int-l {
				rockchip,pins = <0x1 0x15 0x0 0xbd>;
				phandle = <0x8b>;
			};
		};

		sdio-pwrseq {

			wifi-enable-h {
				rockchip,pins = <0x0 0xa 0x0 0xba>;
				phandle = <0xc6>;
			};
		};

		usb2 {

			vcc5v0-host-en {
				rockchip,pins = <0x1 0x0 0x0 0xba>;
				phandle = <0xca>;
			};

			vcc-sys-en {
				rockchip,pins = <0x2 0x6 0x0 0xba>;
				phandle = <0xce>;
			};

			hub-rst {
				rockchip,pins = <0x2 0x4 0x0 0xc0>;
				phandle = <0xcb>;
			};
		};

		usb-typec {

			vcc-vbus-typec1-en {
				rockchip,pins = <0x1 0xd 0x0 0xba>;
				phandle = <0xcd>;
			};
		};

		fusb30x {

			fusb0-int {
				rockchip,pins = <0x1 0x2 0x0 0xbd>;
				phandle = <0x42>;
			};

			fusb1-int {
				rockchip,pins = <0x1 0x1 0x0 0xbd>;
				phandle = <0x8f>;
			};
		};

		ngff {

			vcc3v3-ngff-en {
				rockchip,pins = <0x4 0x1b 0x0 0xba>;
				phandle = <0xd0>;
			};
		};

		bt {

			bt-host-wake-l {
				rockchip,pins = <0x0 0x4 0x0 0xba>;
				phandle = <0x4a>;
			};

			bt-reg-on-h {
				rockchip,pins = <0x0 0x9 0x0 0xba>;
				phandle = <0x49>;
			};

			bt-wake-l {
				rockchip,pins = <0x2 0x1a 0x0 0xba>;
				phandle = <0x4b>;
			};
		};

		rt5640 {

			rt5640-hpcon {
				rockchip,pins = <0x4 0x15 0x0 0xba>;
				phandle = <0x3b>;
			};
		};

		wifi {

			wifi-host-wake-l {
				rockchip,pins = <0x0 0x3 0x0 0xba>;
				phandle = <0x26>;
			};
		};
	};

	rockchip-suspend {
		compatible = "rockchip,pm-rk3399";
		status = "disabled";
		rockchip,sleep-debug-en = <0x0>;
		rockchip,virtual-poweroff = <0x0>;
		rockchip,sleep-mode-config = <0xfe>;
		rockchip,wakeup-config = <0x4>;
		phandle = <0x162>;
	};

	opp-table0 {
		compatible = "operating-points-v2";
		opp-shared;
		phandle = <0xb>;

		opp00 {
			opp-hz = <0x0 0x18519600>;
			opp-microvolt = <0xc96a8>;
			clock-latency-ns = <0x9c40>;
		};

		opp01 {
			opp-hz = <0x0 0x23c34600>;
			opp-microvolt = <0xc96a8>;
		};

		opp02 {
			opp-hz = <0x0 0x30a32c00>;
			opp-microvolt = <0xcf850>;
		};

		opp03 {
			opp-hz = <0x0 0x3c14dc00>;
			opp-microvolt = <0xe1d48>;
		};

		opp04 {
			opp-hz = <0x0 0x47868c00>;
			opp-microvolt = <0xf4240>;
		};

		opp05 {
			opp-hz = <0x0 0x54667200>;
			opp-microvolt = <0x112a88>;
		};
	};

	opp-table1 {
		compatible = "operating-points-v2";
		opp-shared;
		phandle = <0xd>;

		opp00 {
			opp-hz = <0x0 0x18519600>;
			opp-microvolt = <0xc96a8>;
			clock-latency-ns = <0x9c40>;
		};

		opp01 {
			opp-hz = <0x0 0x23c34600>;
			opp-microvolt = <0xc96a8>;
		};

		opp02 {
			opp-hz = <0x0 0x30a32c00>;
			opp-microvolt = <0xc96a8>;
		};

		opp03 {
			opp-hz = <0x0 0x3c14dc00>;
			opp-microvolt = <0xd59f8>;
		};

		opp04 {
			opp-hz = <0x0 0x47868c00>;
			opp-microvolt = <0xe7ef0>;
		};

		opp05 {
			opp-hz = <0x0 0x54667200>;
			opp-microvolt = <0xfa3e8>;
		};

		opp06 {
			opp-hz = <0x0 0x5fd82200>;
			opp-microvolt = <0x10c8e0>;
		};

		opp07 {
			opp-hz = <0x0 0x6b49d200>;
			opp-microvolt = <0x124f80>;
		};
	};

	opp-table2 {
		compatible = "operating-points-v2";
		phandle = <0xb8>;

		opp00 {
			opp-hz = <0x0 0xbebc200>;
			opp-microvolt = <0xc3500>;
		};

		opp01 {
			opp-hz = <0x0 0x11b3dc40>;
			opp-microvolt = <0xc3500>;
		};

		opp02 {
			opp-hz = <0x0 0x17d78400>;
			opp-microvolt = <0xc96a8>;
		};

		opp03 {
			opp-hz = <0x0 0x1dcd6500>;
			opp-microvolt = <0xd59f8>;
		};

		opp04 {
			opp-hz = <0x0 0x23c34600>;
			opp-microvolt = <0xe1d48>;
		};

		opp05 {
			opp-hz = <0x0 0x2faf0800>;
			opp-microvolt = <0x10c8e0>;
		};
	};

	chosen {
		stdout-path = "serial2:1500000n8";
	};

	backlight {
		compatible = "pwm-backlight";
		pwms = <0xc1 0x0 0x61a8 0x0>;
		phandle = <0x163>;
	};

	external-gmac-clock {
		compatible = "fixed-clock";
		clock-frequency = <0x7735940>;
		clock-output-names = "clkin_gmac";
		#clock-cells = <0x0>;
		phandle = <0x1d>;
	};

	adc-keys {
		compatible = "adc-keys";
		io-channels = <0xc2 0x1>;
		io-channel-names = "buttons";
		keyup-threshold-microvolt = <0x16e360>;
		poll-interval = <0x64>;

		recovery {
			label = "Recovery";
			linux,code = <0x168>;
			press-threshold-microvolt = <0x4650>;
		};
	};

	gpio-keys {
		compatible = "gpio-keys";
		autorepeat;
		pinctrl-names = "default";
		pinctrl-0 = <0xc3>;

		power {
			debounce-interval = <0x64>;
			gpios = <0x25 0x5 0x1>;
			label = "GPIO Key Power";
			linux,code = <0x74>;
			wakeup-source;
		};
	};

	leds {
		compatible = "gpio-leds";
		pinctrl-names = "default";
		pinctrl-0 = <0xc4 0xc5>;

		led-0 {
			label = "work";
			gpios = <0x48 0x1b 0x0>;
			default-state = "on";
			linux,default-trigger = "heartbeat";
			phandle = <0x164>;
		};

		led-1 {
			label = "diy";
			gpios = <0x25 0xd 0x0>;
			default-state = "off";
			linux,default-trigger = "mmc2";
			phandle = <0x165>;
		};

		led-2 {
			label = "yellow:yellow-led";
			gpios = <0x25 0x2 0x0>;
			default-state = "off";
			linux,default-trigger = "mmc1";
			phandle = <0x166>;
		};
	};

	sdio-pwrseq {
		compatible = "mmc-pwrseq-simple";
		clocks = <0x47 0x1>;
		clock-names = "ext_clock";
		pinctrl-names = "default";
		pinctrl-0 = <0xc6>;
		reset-gpios = <0x25 0xa 0x1>;
		phandle = <0x21>;
	};

	vcc-vbus-typec0 {
		compatible = "regulator-fixed";
		regulator-name = "vcc_vbus_typec0";
		regulator-always-on;
		regulator-boot-on;
		regulator-min-microvolt = <0x4c4b40>;
		regulator-max-microvolt = <0x4c4b40>;
		phandle = <0x43>;
	};

	sys-12v {
		compatible = "regulator-fixed";
		regulator-name = "sys_12v";
		regulator-always-on;
		regulator-boot-on;
		vin-supply = <0xc7>;
		phandle = <0xc9>;
	};

	vcc1v8-s3 {
		compatible = "regulator-fixed";
		regulator-name = "vcc1v8_s3";
		regulator-always-on;
		regulator-boot-on;
		regulator-min-microvolt = <0x1b7740>;
		regulator-max-microvolt = <0x1b7740>;
		vin-supply = <0x4d>;
		phandle = <0x39>;
	};

	vcc3v0-sd {
		compatible = "regulator-fixed";
		enable-active-high;
		gpio = <0x16 0x1e 0x0>;
		pinctrl-names = "default";
		pinctrl-0 = <0xc8>;
		regulator-name = "vcc3v0_sd";
		regulator-boot-on;
		regulator-min-microvolt = <0x2dc6c0>;
		regulator-max-microvolt = <0x2dc6c0>;
		vin-supply = <0x4c>;
		phandle = <0x2a>;
	};

	vcc3v3-sys {
		compatible = "regulator-fixed";
		regulator-name = "vcc3v3_sys";
		regulator-always-on;
		regulator-boot-on;
		regulator-min-microvolt = <0x325aa0>;
		regulator-max-microvolt = <0x325aa0>;
		vin-supply = <0xc9>;
		phandle = <0x4c>;
	};

	vcca-0v9 {
		compatible = "regulator-fixed";
		regulator-name = "vcca_0v9";
		regulator-always-on;
		regulator-boot-on;
		regulator-min-microvolt = <0xdbba0>;
		regulator-max-microvolt = <0xdbba0>;
		vin-supply = <0x4c>;
		phandle = <0x1a>;
	};

	vcc5v0-host-regulator {
		compatible = "regulator-fixed";
		enable-active-high;
		gpio = <0x41 0x0 0x0>;
		pinctrl-names = "default";
		pinctrl-0 = <0xca 0xcb>;
		regulator-name = "vcc5v0_host";
		vin-supply = <0xcc>;
		phandle = <0x9a>;
	};

	vcc-vbus-typec1 {
		compatible = "regulator-fixed";
		enable-active-high;
		gpio = <0x41 0xd 0x0>;
		pinctrl-names = "default";
		pinctrl-0 = <0xcd>;
		regulator-name = "vcc_vbus_typec1";
		regulator-always-on;
		vin-supply = <0xcc>;
		phandle = <0x90>;
	};

	vcc-sys {
		compatible = "regulator-fixed";
		enable-active-high;
		gpio = <0x48 0x6 0x0>;
		pinctrl-names = "default";
		pinctrl-0 = <0xce>;
		regulator-name = "vcc_sys";
		regulator-boot-on;
		regulator-min-microvolt = <0x4c4b40>;
		regulator-max-microvolt = <0x4c4b40>;
		vin-supply = <0xc9>;
		phandle = <0xcc>;
	};

	vdd-log {
		compatible = "pwm-regulator";
		pwms = <0xcf 0x0 0x61a8 0x1>;
		regulator-name = "vdd_log";
		regulator-always-on;
		regulator-boot-on;
		regulator-min-microvolt = <0x6ddd0>;
		regulator-max-microvolt = <0x155cc0>;
		pwm-supply = <0x4c>;
		phandle = <0x167>;
	};

	poe-12v {
		compatible = "regulator-fixed";
		regulator-name = "poe_12v";
		regulator-always-on;
		regulator-boot-on;
		regulator-min-microvolt = <0xb71b00>;
		regulator-max-microvolt = <0xb71b00>;
		phandle = <0xc7>;
	};

	vcc3v3-ngff {
		compatible = "regulator-fixed";
		regulator-name = "vcc3v3_ngff";
		enable-active-high;
		gpio = <0x16 0x1b 0x0>;
		pinctrl-names = "default";
		pinctrl-0 = <0xd0>;
		regulator-always-on;
		regulator-boot-on;
		regulator-min-microvolt = <0x325aa0>;
		regulator-max-microvolt = <0x325aa0>;
		vin-supply = <0xc9>;
		phandle = <0x168>;
	};

	vcc3v3-pcie {
		compatible = "regulator-fixed";
		regulator-name = "vcc3v3_pcie";
		enable-active-high;
		gpio = <0x41 0x11 0x0>;
		pinctrl-names = "default";
		pinctrl-0 = <0xd1>;
		regulator-min-microvolt = <0x325aa0>;
		regulator-max-microvolt = <0x325aa0>;
		vin-supply = <0xc9>;
		phandle = <0x18>;
	};

	rt5640-sound {
		compatible = "simple-audio-card";
		simple-audio-card,name = "rockchip,rt5640-codec";
		simple-audio-card,format = "i2s";
		simple-audio-card,mclk-fs = <0x100>;
		simple-audio-card,widgets = "Microphone", "Mic Jack", "Headphone", "Headphone Jack";
		simple-audio-card,routing = "Mic Jack", "MICBIAS1", "IN1P", "Mic Jack", "Headphone Jack", "HPOL", "Headphone Jack", "HPOR";

		simple-audio-card,cpu {
			sound-dai = <0xd2>;
		};

		simple-audio-card,codec {
			sound-dai = <0xd3>;
		};
	};

	__symbols__ {
		cpu_l0 = "/cpus/cpu@0";
		cpu_l1 = "/cpus/cpu@1";
		cpu_l2 = "/cpus/cpu@2";
		cpu_l3 = "/cpus/cpu@3";
		cpu_b0 = "/cpus/cpu@100";
		cpu_b1 = "/cpus/cpu@101";
		CPU_SLEEP = "/cpus/idle-states/cpu-sleep";
		CLUSTER_SLEEP = "/cpus/idle-states/cluster-sleep";
		xin24m = "/xin24m";
		amba = "/bus";
		dmac_bus = "/bus/dma-controller@ff6d0000";
		dmac_peri = "/bus/dma-controller@ff6e0000";
		pcie0 = "/pcie@f8000000";
		pcie0_intc = "/pcie@f8000000/interrupt-controller";
		gmac = "/ethernet@fe300000";
		sdio0 = "/mmc@fe310000";
		brcmf = "/mmc@fe310000/wifi@1";
		sdmmc = "/mmc@fe320000";
		sdhci = "/sdhci@fe330000";
		usb_host0_ehci = "/usb@fe380000";
		usb_host0_ohci = "/usb@fe3a0000";
		usb_host1_ehci = "/usb@fe3c0000";
		usb_host1_ohci = "/usb@fe3e0000";
		usbdrd3_0 = "/usb@fe800000";
		usbdrd_dwc3_0 = "/usb@fe800000/usb@fe800000";
		usbdrd3_1 = "/usb@fe900000";
		usbdrd_dwc3_1 = "/usb@fe900000/usb@fe900000";
		cdn_dp = "/dp@fec00000";
		dp_in = "/dp@fec00000/ports/port";
		dp_in_vopb = "/dp@fec00000/ports/port/endpoint@0";
		dp_in_vopl = "/dp@fec00000/ports/port/endpoint@1";
		gic = "/interrupt-controller@fee00000";
		its = "/interrupt-controller@fee00000/interrupt-controller@fee20000";
		ppi_cluster0 = "/interrupt-controller@fee00000/ppi-partitions/interrupt-partition-0";
		ppi_cluster1 = "/interrupt-controller@fee00000/ppi-partitions/interrupt-partition-1";
		saradc = "/saradc@ff100000";
		i2c1 = "/i2c@ff110000";
		rt5640 = "/i2c@ff110000/rt5640@1c";
		i2c2 = "/i2c@ff120000";
		i2c3 = "/i2c@ff130000";
		i2c5 = "/i2c@ff140000";
		i2c6 = "/i2c@ff150000";
		i2c7 = "/i2c@ff160000";
		fusb0 = "/i2c@ff160000/usb-typec@22";
		mp8859 = "/i2c@ff160000/regulator@66";
		dc_12v = "/i2c@ff160000/regulator@66/mp8859_dcdc";
		uart0 = "/serial@ff180000";
		uart1 = "/serial@ff190000";
		uart2 = "/serial@ff1a0000";
		uart3 = "/serial@ff1b0000";
		spi0 = "/spi@ff1c0000";
		spi1 = "/spi@ff1d0000";
		spi2 = "/spi@ff1e0000";
		spi4 = "/spi@ff1f0000";
		spi5 = "/spi@ff200000";
		thermal_zones = "/thermal-zones";
		cpu_thermal = "/thermal-zones/cpu";
		cpu_alert0 = "/thermal-zones/cpu/trips/cpu_alert0";
		cpu_alert1 = "/thermal-zones/cpu/trips/cpu_alert1";
		cpu_crit = "/thermal-zones/cpu/trips/cpu_crit";
		gpu_thermal = "/thermal-zones/gpu";
		gpu_alert0 = "/thermal-zones/gpu/trips/gpu_alert0";
		gpu_crit = "/thermal-zones/gpu/trips/gpu_crit";
		tsadc = "/tsadc@ff260000";
		qos_emmc = "/qos@ffa58000";
		qos_gmac = "/qos@ffa5c000";
		qos_pcie = "/qos@ffa60080";
		qos_usb_host0 = "/qos@ffa60100";
		qos_usb_host1 = "/qos@ffa60180";
		qos_usb_otg0 = "/qos@ffa70000";
		qos_usb_otg1 = "/qos@ffa70080";
		qos_sd = "/qos@ffa74000";
		qos_sdioaudio = "/qos@ffa76000";
		qos_hdcp = "/qos@ffa90000";
		qos_iep = "/qos@ffa98000";
		qos_isp0_m0 = "/qos@ffaa0000";
		qos_isp0_m1 = "/qos@ffaa0080";
		qos_isp1_m0 = "/qos@ffaa8000";
		qos_isp1_m1 = "/qos@ffaa8080";
		qos_rga_r = "/qos@ffab0000";
		qos_rga_w = "/qos@ffab0080";
		qos_video_m0 = "/qos@ffab8000";
		qos_video_m1_r = "/qos@ffac0000";
		qos_video_m1_w = "/qos@ffac0080";
		qos_vop_big_r = "/qos@ffac8000";
		qos_vop_big_w = "/qos@ffac8080";
		qos_vop_little = "/qos@ffad0000";
		qos_perihp = "/qos@ffad8080";
		qos_gpu = "/qos@ffae0000";
		pmu = "/power-management@ff310000";
		power = "/power-management@ff310000/power-controller";
		pmugrf = "/syscon@ff320000";
		pmu_io_domains = "/syscon@ff320000/io-domains";
		spi3 = "/spi@ff350000";
		uart4 = "/serial@ff370000";
		i2c0 = "/i2c@ff3c0000";
		rk808 = "/i2c@ff3c0000/pmic@1b";
		vdd_center = "/i2c@ff3c0000/pmic@1b/regulators/DCDC_REG1";
		vdd_cpu_l = "/i2c@ff3c0000/pmic@1b/regulators/DCDC_REG2";
		vcc_ddr = "/i2c@ff3c0000/pmic@1b/regulators/DCDC_REG3";
		vcc_1v8 = "/i2c@ff3c0000/pmic@1b/regulators/DCDC_REG4";
		vcca1v8_codec = "/i2c@ff3c0000/pmic@1b/regulators/LDO_REG1";
		vcc1v8_hdmi = "/i2c@ff3c0000/pmic@1b/regulators/LDO_REG2";
		vcc1v8_pmu = "/i2c@ff3c0000/pmic@1b/regulators/LDO_REG3";
		vcc_sdio = "/i2c@ff3c0000/pmic@1b/regulators/LDO_REG4";
		vcca3v0_codec = "/i2c@ff3c0000/pmic@1b/regulators/LDO_REG5";
		vcc_1v5 = "/i2c@ff3c0000/pmic@1b/regulators/LDO_REG6";
		vcca0v9_hdmi = "/i2c@ff3c0000/pmic@1b/regulators/LDO_REG7";
		vcc_3v0 = "/i2c@ff3c0000/pmic@1b/regulators/LDO_REG8";
		vcc3v3_s3 = "/i2c@ff3c0000/pmic@1b/regulators/SWITCH_REG1";
		vcc_lan = "/i2c@ff3c0000/pmic@1b/regulators/SWITCH_REG1";
		vcc3v3_s0 = "/i2c@ff3c0000/pmic@1b/regulators/SWITCH_REG2";
		vdd_cpu_b = "/i2c@ff3c0000/regulator@40";
		vdd_gpu = "/i2c@ff3c0000/regulator@41";
		hym8563 = "/i2c@ff3c0000/hym8563@51";
		i2c4 = "/i2c@ff3d0000";
		fusb1 = "/i2c@ff3d0000/usb-typec@22";
		i2c8 = "/i2c@ff3e0000";
		pwm0 = "/pwm@ff420000";
		pwm1 = "/pwm@ff420010";
		pwm2 = "/pwm@ff420020";
		pwm3 = "/pwm@ff420030";
		vpu = "/video-codec@ff650000";
		vpu_mmu = "/iommu@ff650800";
		vdec = "/video-codec@ff660000";
		vdec_mmu = "/iommu@ff660480";
		iep_mmu = "/iommu@ff670800";
		rga = "/rga@ff680000";
		efuse0 = "/efuse@ff690000";
		cpu_id = "/efuse@ff690000/cpu-id@7";
		cpub_leakage = "/efuse@ff690000/cpu-leakage@17";
		gpu_leakage = "/efuse@ff690000/gpu-leakage@18";
		center_leakage = "/efuse@ff690000/center-leakage@19";
		cpul_leakage = "/efuse@ff690000/cpu-leakage@1a";
		logic_leakage = "/efuse@ff690000/logic-leakage@1b";
		wafer_info = "/efuse@ff690000/wafer-info@1c";
		pmucru = "/pmu-clock-controller@ff750000";
		cru = "/clock-controller@ff760000";
		grf = "/syscon@ff770000";
		io_domains = "/syscon@ff770000/io-domains";
		mipi_dphy_rx0 = "/syscon@ff770000/mipi-dphy-rx0";
		u2phy0 = "/syscon@ff770000/usb2-phy@e450";
		u2phy0_host = "/syscon@ff770000/usb2-phy@e450/host-port";
		u2phy0_otg = "/syscon@ff770000/usb2-phy@e450/otg-port";
		u2phy1 = "/syscon@ff770000/usb2-phy@e460";
		u2phy1_host = "/syscon@ff770000/usb2-phy@e460/host-port";
		u2phy1_otg = "/syscon@ff770000/usb2-phy@e460/otg-port";
		emmc_phy = "/syscon@ff770000/phy@f780";
		pcie_phy = "/syscon@ff770000/pcie-phy";
		tcphy0 = "/phy@ff7c0000";
		tcphy0_dp = "/phy@ff7c0000/dp-port";
		tcphy0_usb3 = "/phy@ff7c0000/usb3-port";
		tcphy1 = "/phy@ff800000";
		tcphy1_dp = "/phy@ff800000/dp-port";
		tcphy1_usb3 = "/phy@ff800000/usb3-port";
		rktimer = "/rktimer@ff850000";
		spdif = "/spdif@ff870000";
		i2s0 = "/i2s@ff880000";
		i2s1 = "/i2s@ff890000";
		i2s2 = "/i2s@ff8a0000";
		vopl = "/vop@ff8f0000";
		vopl_out = "/vop@ff8f0000/port";
		vopl_out_mipi = "/vop@ff8f0000/port/endpoint@0";
		vopl_out_edp = "/vop@ff8f0000/port/endpoint@1";
		vopl_out_hdmi = "/vop@ff8f0000/port/endpoint@2";
		vopl_out_mipi1 = "/vop@ff8f0000/port/endpoint@3";
		vopl_out_dp = "/vop@ff8f0000/port/endpoint@4";
		vopl_mmu = "/iommu@ff8f3f00";
		vopb = "/vop@ff900000";
		vopb_out = "/vop@ff900000/port";
		vopb_out_edp = "/vop@ff900000/port/endpoint@0";
		vopb_out_mipi = "/vop@ff900000/port/endpoint@1";
		vopb_out_hdmi = "/vop@ff900000/port/endpoint@2";
		vopb_out_mipi1 = "/vop@ff900000/port/endpoint@3";
		vopb_out_dp = "/vop@ff900000/port/endpoint@4";
		vopb_mmu = "/iommu@ff903f00";
		isp0_mmu = "/iommu@ff914000";
		isp1_mmu = "/iommu@ff924000";
		hdmi_sound = "/hdmi-sound";
		hdmi = "/hdmi@ff940000";
		hdmi_in = "/hdmi@ff940000/ports/port";
		hdmi_in_vopb = "/hdmi@ff940000/ports/port/endpoint@0";
		hdmi_in_vopl = "/hdmi@ff940000/ports/port/endpoint@1";
		mipi_dsi = "/mipi@ff960000";
		mipi_in = "/mipi@ff960000/ports/port@0";
		mipi_in_vopb = "/mipi@ff960000/ports/port@0/endpoint@0";
		mipi_in_vopl = "/mipi@ff960000/ports/port@0/endpoint@1";
		mipi_dsi1 = "/mipi@ff968000";
		mipi1_in = "/mipi@ff968000/ports/port@0";
		mipi1_in_vopb = "/mipi@ff968000/ports/port@0/endpoint@0";
		mipi1_in_vopl = "/mipi@ff968000/ports/port@0/endpoint@1";
		edp = "/edp@ff970000";
		edp_in = "/edp@ff970000/ports/port@0";
		edp_in_vopb = "/edp@ff970000/ports/port@0/endpoint@0";
		edp_in_vopl = "/edp@ff970000/ports/port@0/endpoint@1";
		gpu = "/gpu@ff9a0000";
		pinctrl = "/pinctrl";
		gpio0 = "/pinctrl/gpio0@ff720000";
		gpio1 = "/pinctrl/gpio1@ff730000";
		gpio2 = "/pinctrl/gpio2@ff780000";
		gpio3 = "/pinctrl/gpio3@ff788000";
		gpio4 = "/pinctrl/gpio4@ff790000";
		pcfg_pull_up = "/pinctrl/pcfg-pull-up";
		pcfg_pull_down = "/pinctrl/pcfg-pull-down";
		pcfg_pull_none = "/pinctrl/pcfg-pull-none";
		pcfg_pull_none_12ma = "/pinctrl/pcfg-pull-none-12ma";
		pcfg_pull_none_13ma = "/pinctrl/pcfg-pull-none-13ma";
		pcfg_pull_none_18ma = "/pinctrl/pcfg-pull-none-18ma";
		pcfg_pull_none_20ma = "/pinctrl/pcfg-pull-none-20ma";
		pcfg_pull_up_2ma = "/pinctrl/pcfg-pull-up-2ma";
		pcfg_pull_up_8ma = "/pinctrl/pcfg-pull-up-8ma";
		pcfg_pull_up_18ma = "/pinctrl/pcfg-pull-up-18ma";
		pcfg_pull_up_20ma = "/pinctrl/pcfg-pull-up-20ma";
		pcfg_pull_down_4ma = "/pinctrl/pcfg-pull-down-4ma";
		pcfg_pull_down_8ma = "/pinctrl/pcfg-pull-down-8ma";
		pcfg_pull_down_12ma = "/pinctrl/pcfg-pull-down-12ma";
		pcfg_pull_down_18ma = "/pinctrl/pcfg-pull-down-18ma";
		pcfg_pull_down_20ma = "/pinctrl/pcfg-pull-down-20ma";
		pcfg_output_high = "/pinctrl/pcfg-output-high";
		pcfg_output_low = "/pinctrl/pcfg-output-low";
		clk_32k = "/pinctrl/clock/clk-32k";
		edp_hpd = "/pinctrl/edp/edp-hpd";
		rgmii_pins = "/pinctrl/gmac/rgmii-pins";
		rmii_pins = "/pinctrl/gmac/rmii-pins";
		i2c0_xfer = "/pinctrl/i2c0/i2c0-xfer";
		i2c1_xfer = "/pinctrl/i2c1/i2c1-xfer";
		i2c2_xfer = "/pinctrl/i2c2/i2c2-xfer";
		i2c3_xfer = "/pinctrl/i2c3/i2c3-xfer";
		i2c4_xfer = "/pinctrl/i2c4/i2c4-xfer";
		i2c5_xfer = "/pinctrl/i2c5/i2c5-xfer";
		i2c6_xfer = "/pinctrl/i2c6/i2c6-xfer";
		i2c7_xfer = "/pinctrl/i2c7/i2c7-xfer";
		i2c8_xfer = "/pinctrl/i2c8/i2c8-xfer";
		i2s0_2ch_bus = "/pinctrl/i2s0/i2s0-2ch-bus";
		i2s0_8ch_bus = "/pinctrl/i2s0/i2s0-8ch-bus";
		i2s1_2ch_bus = "/pinctrl/i2s1/i2s1-2ch-bus";
		sdio0_bus1 = "/pinctrl/sdio0/sdio0-bus1";
		sdio0_bus4 = "/pinctrl/sdio0/sdio0-bus4";
		sdio0_cmd = "/pinctrl/sdio0/sdio0-cmd";
		sdio0_clk = "/pinctrl/sdio0/sdio0-clk";
		sdio0_cd = "/pinctrl/sdio0/sdio0-cd";
		sdio0_pwr = "/pinctrl/sdio0/sdio0-pwr";
		sdio0_bkpwr = "/pinctrl/sdio0/sdio0-bkpwr";
		sdio0_wp = "/pinctrl/sdio0/sdio0-wp";
		sdio0_int = "/pinctrl/sdio0/sdio0-int";
		sdmmc_bus1 = "/pinctrl/sdmmc/sdmmc-bus1";
		sdmmc_bus4 = "/pinctrl/sdmmc/sdmmc-bus4";
		sdmmc_clk = "/pinctrl/sdmmc/sdmmc-clk";
		sdmmc_cmd = "/pinctrl/sdmmc/sdmmc-cmd";
		sdmmc_cd = "/pinctrl/sdmmc/sdmmc-cd";
		sdmmc_wp = "/pinctrl/sdmmc/sdmmc-wp";
		vcc3v0_sd_en = "/pinctrl/sdmmc/vcc3v0-sd-en";
		ap_pwroff = "/pinctrl/suspend/ap-pwroff";
		ddrio_pwroff = "/pinctrl/suspend/ddrio-pwroff";
		spdif_bus = "/pinctrl/spdif/spdif-bus";
		spdif_bus_1 = "/pinctrl/spdif/spdif-bus-1";
		spi0_clk = "/pinctrl/spi0/spi0-clk";
		spi0_cs0 = "/pinctrl/spi0/spi0-cs0";
		spi0_cs1 = "/pinctrl/spi0/spi0-cs1";
		spi0_tx = "/pinctrl/spi0/spi0-tx";
		spi0_rx = "/pinctrl/spi0/spi0-rx";
		spi1_clk = "/pinctrl/spi1/spi1-clk";
		spi1_cs0 = "/pinctrl/spi1/spi1-cs0";
		spi1_rx = "/pinctrl/spi1/spi1-rx";
		spi1_tx = "/pinctrl/spi1/spi1-tx";
		spi2_clk = "/pinctrl/spi2/spi2-clk";
		spi2_cs0 = "/pinctrl/spi2/spi2-cs0";
		spi2_rx = "/pinctrl/spi2/spi2-rx";
		spi2_tx = "/pinctrl/spi2/spi2-tx";
		spi3_clk = "/pinctrl/spi3/spi3-clk";
		spi3_cs0 = "/pinctrl/spi3/spi3-cs0";
		spi3_rx = "/pinctrl/spi3/spi3-rx";
		spi3_tx = "/pinctrl/spi3/spi3-tx";
		spi4_clk = "/pinctrl/spi4/spi4-clk";
		spi4_cs0 = "/pinctrl/spi4/spi4-cs0";
		spi4_rx = "/pinctrl/spi4/spi4-rx";
		spi4_tx = "/pinctrl/spi4/spi4-tx";
		spi5_clk = "/pinctrl/spi5/spi5-clk";
		spi5_cs0 = "/pinctrl/spi5/spi5-cs0";
		spi5_rx = "/pinctrl/spi5/spi5-rx";
		spi5_tx = "/pinctrl/spi5/spi5-tx";
		test_clkout0 = "/pinctrl/testclk/test-clkout0";
		test_clkout1 = "/pinctrl/testclk/test-clkout1";
		test_clkout2 = "/pinctrl/testclk/test-clkout2";
		otp_pin = "/pinctrl/tsadc/otp-pin";
		otp_out = "/pinctrl/tsadc/otp-out";
		uart0_xfer = "/pinctrl/uart0/uart0-xfer";
		uart0_cts = "/pinctrl/uart0/uart0-cts";
		uart0_rts = "/pinctrl/uart0/uart0-rts";
		uart1_xfer = "/pinctrl/uart1/uart1-xfer";
		uart2a_xfer = "/pinctrl/uart2a/uart2a-xfer";
		uart2b_xfer = "/pinctrl/uart2b/uart2b-xfer";
		uart2c_xfer = "/pinctrl/uart2c/uart2c-xfer";
		uart3_xfer = "/pinctrl/uart3/uart3-xfer";
		uart3_cts = "/pinctrl/uart3/uart3-cts";
		uart3_rts = "/pinctrl/uart3/uart3-rts";
		uart4_xfer = "/pinctrl/uart4/uart4-xfer";
		uarthdcp_xfer = "/pinctrl/uarthdcp/uarthdcp-xfer";
		pwm0_pin = "/pinctrl/pwm0/pwm0-pin";
		pwm0_pin_pull_down = "/pinctrl/pwm0/pwm0-pin-pull-down";
		vop0_pwm_pin = "/pinctrl/pwm0/vop0-pwm-pin";
		vop1_pwm_pin = "/pinctrl/pwm0/vop1-pwm-pin";
		pwm1_pin = "/pinctrl/pwm1/pwm1-pin";
		pwm1_pin_pull_down = "/pinctrl/pwm1/pwm1-pin-pull-down";
		pwm2_pin = "/pinctrl/pwm2/pwm2-pin";
		pwm2_pin_pull_down = "/pinctrl/pwm2/pwm2-pin-pull-down";
		pwm3a_pin = "/pinctrl/pwm3a/pwm3a-pin";
		pwm3b_pin = "/pinctrl/pwm3b/pwm3b-pin";
		hdmi_i2c_xfer = "/pinctrl/hdmi/hdmi-i2c-xfer";
		hdmi_cec = "/pinctrl/hdmi/hdmi-cec";
		pcie_clkreqn_cpm = "/pinctrl/pcie/pci-clkreqn-cpm";
		pcie_clkreqnb_cpm = "/pinctrl/pcie/pci-clkreqnb-cpm";
		vcc3v3_pcie_en = "/pinctrl/pcie/vcc3v3-pcie-en";
		pcie_perst = "/pinctrl/pcie/pcie-perst";
		pcie_pwr_en = "/pinctrl/pcie/pcie-pwr-en";
		pcie_3g_drv = "/pinctrl/pcie/pcie-3g-drv";
		pwr_key_l = "/pinctrl/buttons/pwr-key-l";
		pwrbtn = "/pinctrl/buttons/pwrbtn";
		lcd_panel_reset = "/pinctrl/lcd-panel/lcd-panel-reset";
		diy_led_pin = "/pinctrl/leds/diy-led-pin";
		work_led_pin = "/pinctrl/leds/work-led-pin";
		yellow_led_pin = "/pinctrl/leds/yellow-led-pin";
		vsel1_pin = "/pinctrl/pmic/vsel1-pin";
		vsel2_pin = "/pinctrl/pmic/vsel2-pin";
		pmic_int_l = "/pinctrl/pmic/pmic-int-l";
		wifi_enable_h = "/pinctrl/sdio-pwrseq/wifi-enable-h";
		vcc5v0_host_en = "/pinctrl/usb2/vcc5v0-host-en";
		vcc_sys_en = "/pinctrl/usb2/vcc-sys-en";
		hub_rst = "/pinctrl/usb2/hub-rst";
		vcc_vbus_typec1_en = "/pinctrl/usb-typec/vcc-vbus-typec1-en";
		fusb0_int = "/pinctrl/fusb30x/fusb0-int";
		fusb1_int = "/pinctrl/fusb30x/fusb1-int";
		vcc3v3_ngff_en = "/pinctrl/ngff/vcc3v3-ngff-en";
		bt_host_wake_l = "/pinctrl/bt/bt-host-wake-l";
		bt_reg_on_h = "/pinctrl/bt/bt-reg-on-h";
		bt_wake_l = "/pinctrl/bt/bt-wake-l";
		rt5640_hpcon = "/pinctrl/rt5640/rt5640-hpcon";
		wifi_host_wake_l = "/pinctrl/wifi/wifi-host-wake-l";
		rockchip_suspend = "/rockchip-suspend";
		cluster0_opp = "/opp-table0";
		cluster1_opp = "/opp-table1";
		gpu_opp_table = "/opp-table2";
		backlight = "/backlight";
		clkin_gmac = "/external-gmac-clock";
		work_led = "/leds/led-0";
		diy_led = "/leds/led-1";
		yellow_led = "/leds/led-2";
		sdio_pwrseq = "/sdio-pwrseq";
		vcc_vbus_typec0 = "/vcc-vbus-typec0";
		sys_12v = "/sys-12v";
		vcc1v8_s3 = "/vcc1v8-s3";
		vcca1v8_s3 = "/vcc1v8-s3";
		vcc3v0_sd = "/vcc3v0-sd";
		vcc3v3_sys = "/vcc3v3-sys";
		vcca_0v9 = "/vcca-0v9";
		vcc5v0_host = "/vcc5v0-host-regulator";
		vcc_vbus_typec1 = "/vcc-vbus-typec1";
		vcc_sys = "/vcc-sys";
		vdd_log = "/vdd-log";
		poe_12v = "/poe-12v";
		vcc3v3_ngff = "/vcc3v3-ngff";
		vcc3v3_pcie = "/vcc3v3-pcie";
	};
};
